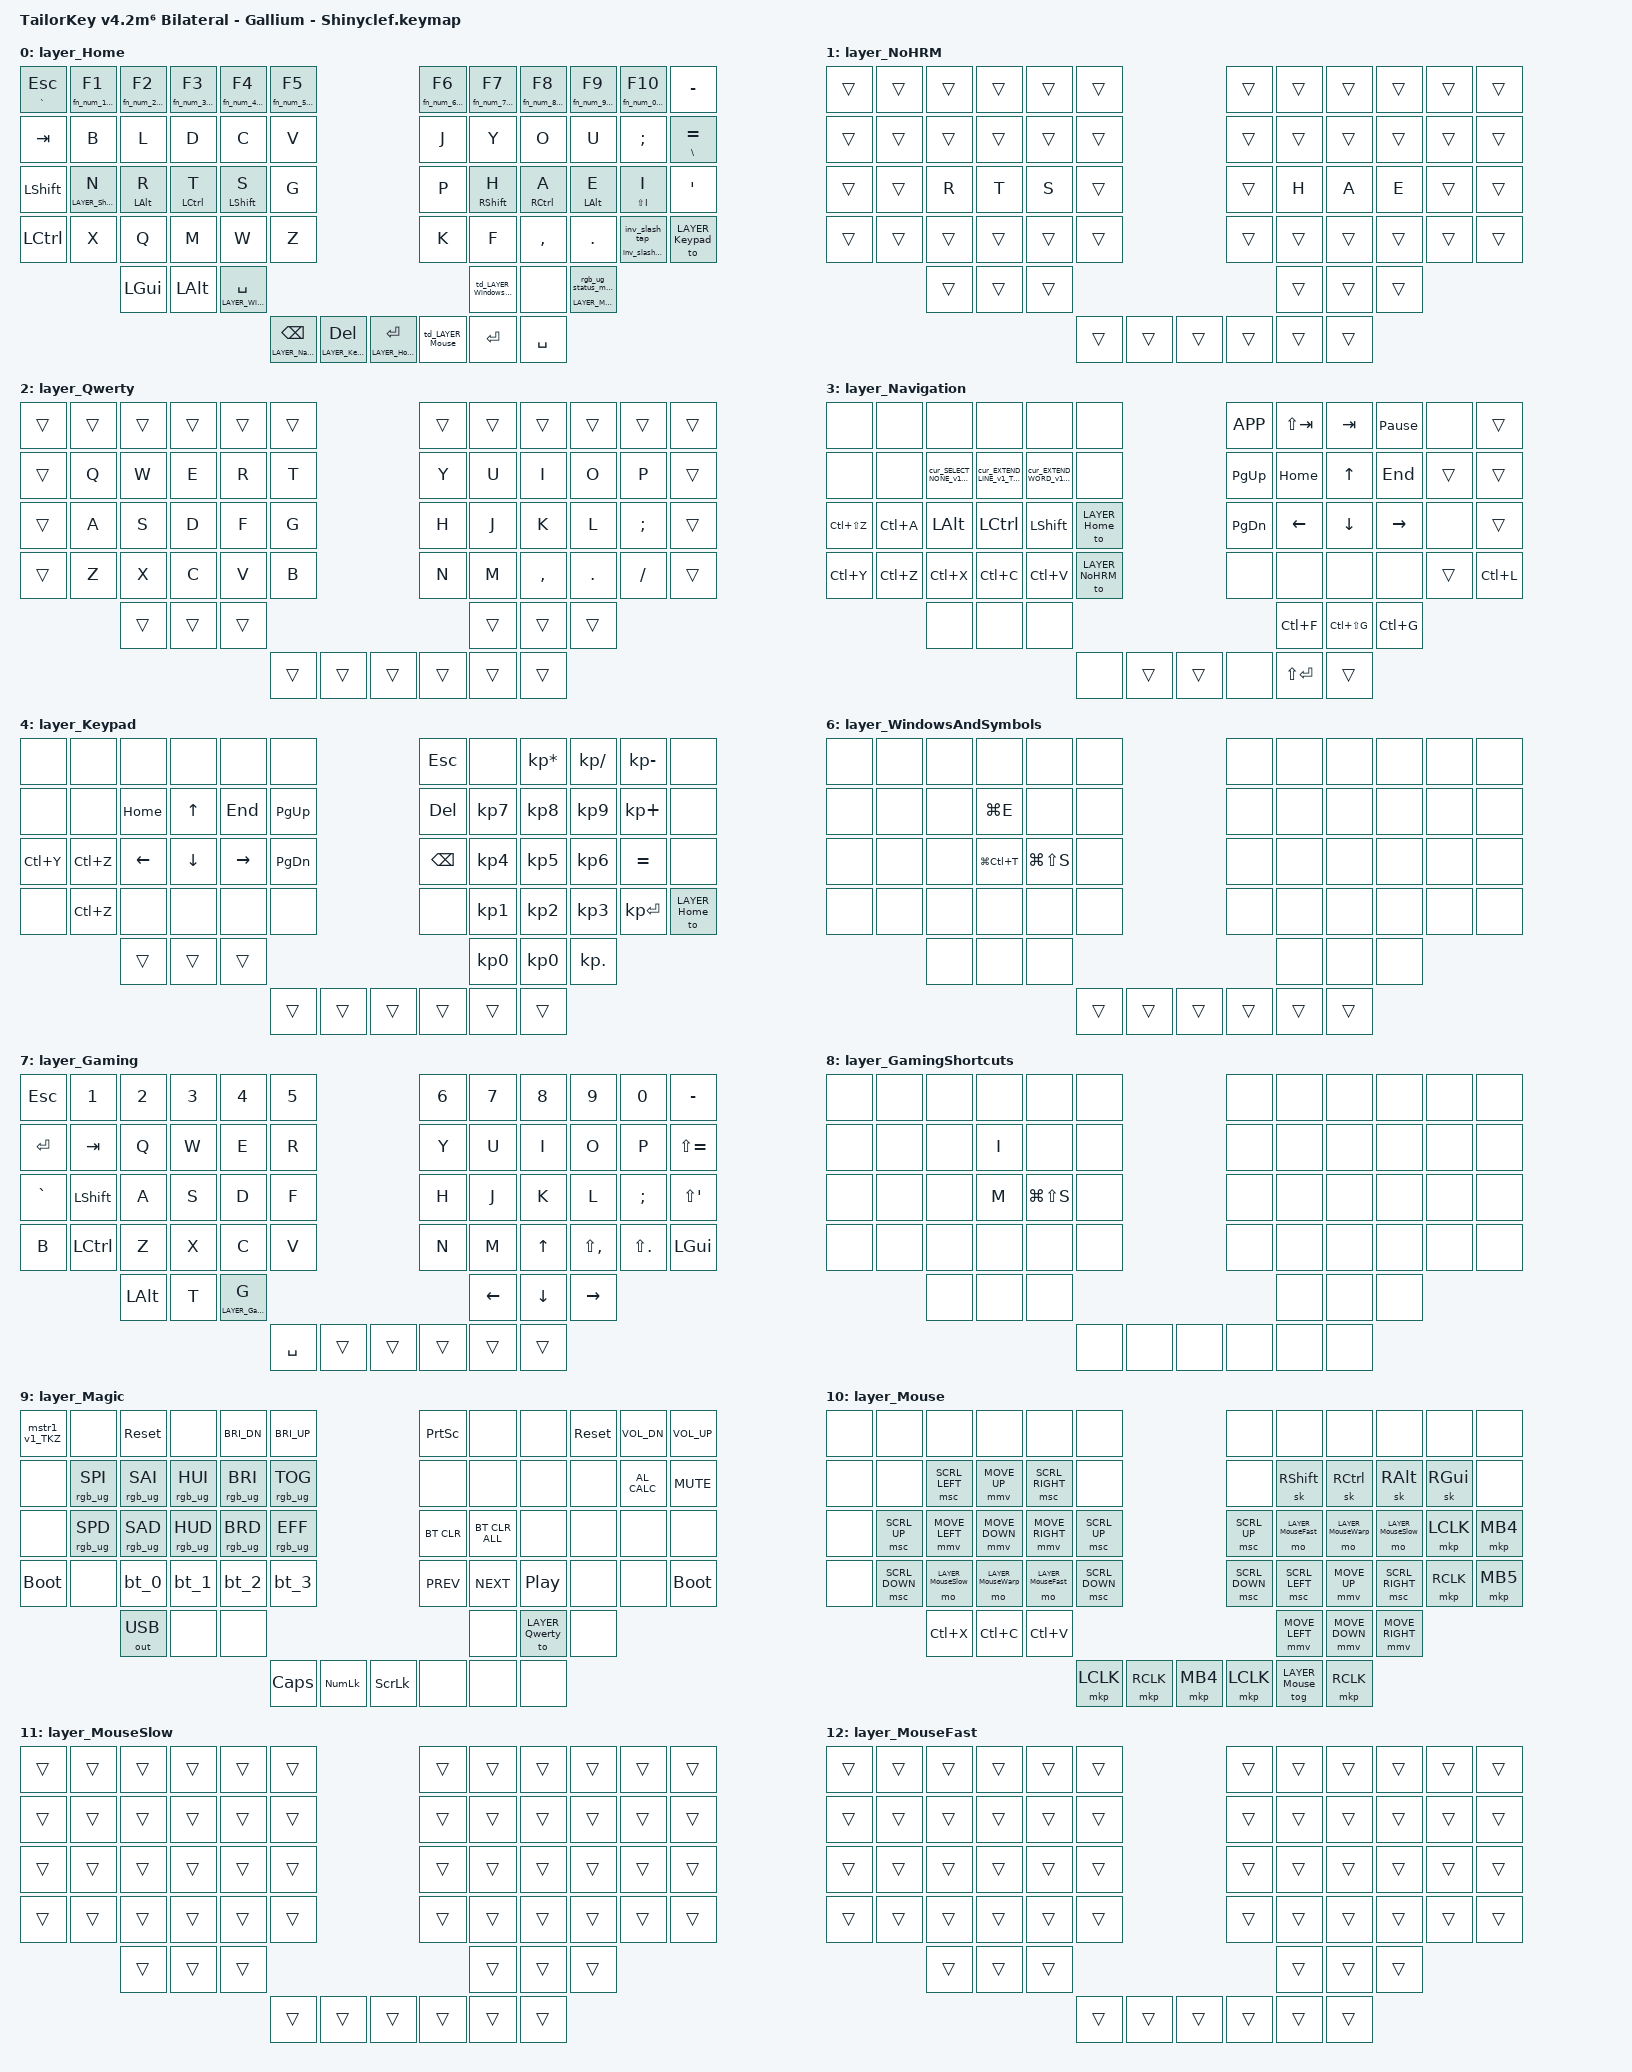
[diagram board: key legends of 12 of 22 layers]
/*
 * Copyright (c) 2020 The ZMK Contributors
 * Copyright (c) 2025 Innaworks Development Limited, trading as MoErgo
 *
 * SPDX-License-Identifier: MIT
 */


/* THIS FILE WAS GENERATED BY GO60 LAYOUT EDITOR
 *
 * This file was generated automatically. You may or may not want to
 * edit it directly.
 */

#include <behaviors.dtsi>

/* Include all behavior includes needed */

#include <dt-bindings/zmk/outputs.h>
#include <dt-bindings/zmk/keys.h>
#include <dt-bindings/zmk/bt.h>
#include <dt-bindings/zmk/rgb.h>

#include <input/processors.dtsi>
#include <dt-bindings/zmk/input_transform.h>
#include <zephyr/dt-bindings/input/input-event-codes.h>

/* On demand includes */
#include <dt-bindings/zmk/input_transform.h>
#include <dt-bindings/zmk/pointing.h>
#include <input/processors.dtsi>

/* Helper Macros, based on https://github.com/urob/zmk-helpers/ */

#pragma once

#define ZMK_HELPER_STRINGIFY(x) #x

// Preprocessor mechanism to overload macros, cf. https://stackoverflow.com/a/27051616/6114651
#define VARGS_(_10, _9, _8, _7, _6, _5, _4, _3, _2, _1, N, ...) N
#define VARGS(...) VARGS_(__VA_ARGS__, 10, 9, 8, 7, 6, 5, 4, 3, 2, 1, 0)
#define CONCAT_(a, b) a##b
#define CONCAT(a, b) CONCAT_(a, b)

#define ZMK_BEHAVIOR_CORE_tap_dance  \
    compatible = "zmk,behavior-tap-dance"; \
    #binding-cells = <0>

#define ZMK_BEHAVIOR(name, type, ...) \
    name: name { \
        ZMK_BEHAVIOR_CORE_ ## type; \
        __VA_ARGS__ \
    };

#define ZMK_TAP_DANCE(name, ...) \
    ZMK_BEHAVIOR(name, tap_dance, __VA_ARGS__)

#define ZMK_TD_LAYER(name, layer) \
    ZMK_TAP_DANCE(name, \
        tapping-term-ms = <200>; \
        bindings = <&mo layer>, <&to layer>; \
)





/* Key positions */

#define POS_LH_C6R1 0
#define POS_LH_C5R1 1
#define POS_LH_C4R1 2
#define POS_LH_C3R1 3
#define POS_LH_C2R1 4
#define POS_LH_C1R1 5
#define POS_RH_C1R1 6
#define POS_RH_C2R1 7
#define POS_RH_C3R1 8
#define POS_RH_C4R1 9
#define POS_RH_C5R1 10
#define POS_RH_C6R1 11
#define POS_LH_C6R2 12
#define POS_LH_C5R2 13
#define POS_LH_C4R2 14
#define POS_LH_C3R2 15
#define POS_LH_C2R2 16
#define POS_LH_C1R2 17
#define POS_RH_C1R2 18
#define POS_RH_C2R2 19
#define POS_RH_C3R2 20
#define POS_RH_C4R2 21
#define POS_RH_C5R2 22
#define POS_RH_C6R2 23
#define POS_LH_C6R3 24
#define POS_LH_C5R3 25
#define POS_LH_C4R3 26
#define POS_LH_C3R3 27
#define POS_LH_C2R3 28
#define POS_LH_C1R3 29
#define POS_RH_C1R3 30
#define POS_RH_C2R3 31
#define POS_RH_C3R3 32
#define POS_RH_C4R3 33
#define POS_RH_C5R3 34
#define POS_RH_C6R3 35
#define POS_LH_C6R4 36
#define POS_LH_C5R4 37
#define POS_LH_C4R4 38
#define POS_LH_C3R4 39
#define POS_LH_C2R4 40
#define POS_LH_C1R4 41
#define POS_RH_C1R4 42
#define POS_RH_C2R4 43
#define POS_RH_C3R4 44
#define POS_RH_C4R4 45
#define POS_RH_C5R4 46
#define POS_RH_C6R4 47
#define POS_LH_C4R5 48
#define POS_LH_C3R5 49
#define POS_LH_C2R5 50
#define POS_RH_C2R5 51
#define POS_RH_C3R5 52
#define POS_RH_C4R5 53
#define POS_LH_T1 54
#define POS_LH_T2 55
#define POS_LH_T3 56
#define POS_RH_T3 57
#define POS_RH_T2 58
#define POS_RH_T1 59


#define LEFT_HAND_KEYS \
  POS_LH_C1R1 POS_LH_C2R1 POS_LH_C3R1 POS_LH_C4R1 POS_LH_C5R1 POS_LH_C6R1 \
  POS_LH_C1R2 POS_LH_C2R2 POS_LH_C3R2 POS_LH_C4R2 POS_LH_C5R2 POS_LH_C6R2 \
  POS_LH_C1R3 POS_LH_C2R3 POS_LH_C3R3 POS_LH_C4R3 POS_LH_C5R3 POS_LH_C6R3 \
  POS_LH_C1R4 POS_LH_C2R4 POS_LH_C3R4 POS_LH_C4R4 POS_LH_C5R4 POS_LH_C6R4 \
              POS_LH_C2R5 POS_LH_C3R5 POS_LH_C4R5

#define RIGHT_HAND_KEYS \
  POS_RH_C1R1 POS_RH_C2R1 POS_RH_C3R1 POS_RH_C4R1 POS_RH_C5R1 POS_RH_C6R1 \
  POS_RH_C1R2 POS_RH_C2R2 POS_RH_C3R2 POS_RH_C4R2 POS_RH_C5R2 POS_RH_C6R2 \
  POS_RH_C1R3 POS_RH_C2R3 POS_RH_C3R3 POS_RH_C4R3 POS_RH_C5R3 POS_RH_C6R3 \
  POS_RH_C1R4 POS_RH_C2R4 POS_RH_C3R4 POS_RH_C4R4 POS_RH_C5R4 POS_RH_C6R4 \
              POS_RH_C2R5 POS_RH_C3R5 POS_RH_C4R5

#define THUMB_KEYS \
  POS_LH_T1 POS_LH_T2 POS_LH_T3 \
  POS_RH_T1 POS_RH_T2 POS_RH_T3

/* Environment and metadata defines */
#define KB_TYPE_GLOVE_80 1
#define KB_TYPE_GO_60    2

#define KB_TYPE          KB_TYPE_GO_60
#define EDITOR_HOST_OS   'W'

/* Automatically generated layer name defines */
#define LAYER_Home 0
#define LAYER_NoHRM 1
#define LAYER_Qwerty 2
#define LAYER_Navigation 3
#define LAYER_Keypad 4
#define LAYER_Shortcuts 5
#define LAYER_WindowsAndSymbols 6
#define LAYER_Gaming 7
#define LAYER_GamingShortcuts 8
#define LAYER_Magic 9
#define LAYER_Mouse 10
#define LAYER_MouseSlow 11
#define LAYER_MouseFast 12
#define LAYER_MouseWarp 13
#define LAYER_LeftPinky 14
#define LAYER_LeftRingy 15
#define LAYER_LeftMiddy 16
#define LAYER_LeftIndex 17
#define LAYER_RightPinky 18
#define LAYER_RightRingy 19
#define LAYER_RightMiddy 20
#define LAYER_RightIndex 21

/* To deal with the situation where there is no Lower layer, to keep &lower happy */
#ifndef LAYER_Lower
#define LAYER_Lower 0
#endif

/* Generated input processors */
/ {
    input_processors {
        zip_click_to_right_click_mapper: zip_click_to_right_click_mapper {
            compatible = "zmk,input-processor-code-mapper";
            #input-processor-cells = <0>;
            type = <INPUT_EV_KEY>;
            map = <INPUT_BTN_0 INPUT_BTN_1>;
        };
    };
};

/* Custom Device-tree */


/* Input Listeners */
&mmv_input_listener {
    // LAYER_MouseSlow
    LAYER_MouseSlow {
        layers = <LAYER_MouseSlow>;
        input-processors = <&zip_xy_scaler 1 9>;
    };
    // LAYER_MouseFast
    LAYER_MouseFast {
        layers = <LAYER_MouseFast>;
        input-processors = <&zip_xy_scaler 3 1>;
    };
    // LAYER_MouseWarp
    LAYER_MouseWarp {
        layers = <LAYER_MouseWarp>;
        input-processors = <&zip_xy_scaler 12 1>;
    };
};

&msc_input_listener {
    // LAYER_MouseSlow
    LAYER_MouseSlow {
        layers = <LAYER_MouseSlow>;
        input-processors = <&zip_scroll_scaler 1 9>;
    };
    // LAYER_MouseFast
    LAYER_MouseFast {
        layers = <LAYER_MouseFast>;
        input-processors = <&zip_scroll_scaler 3 1>;
    };
    // LAYER_MouseWarp
    LAYER_MouseWarp {
        layers = <LAYER_MouseWarp>;
        input-processors = <&zip_scroll_scaler 12 1>;
    };
};

&cirque_lh_listener {
    input-processors = <&zip_xy_scaler 11 12>, <&zip_xy_transform INPUT_TRANSFORM_Y_INVERT>, <&zip_xy_to_scroll_mapper>, <&zip_click_to_right_click_mapper>, <&zip_temp_layer LAYER_Mouse 250>;
    layer_MouseSlow {
        layers = <LAYER_MouseSlow>;
        input-processors = <&zip_xy_scaler 5 14>, <&zip_xy_transform INPUT_TRANSFORM_Y_INVERT>, <&zip_xy_to_scroll_mapper>, <&zip_click_to_right_click_mapper>;
    };
    layer_MouseFast {
        layers = <LAYER_MouseFast>;
        input-processors = <&zip_xy_scaler 3 2>, <&zip_xy_transform INPUT_TRANSFORM_Y_INVERT>, <&zip_xy_to_scroll_mapper>, <&zip_click_to_right_click_mapper>;
    };
    layer_MouseWarp {
        layers = <LAYER_MouseWarp>;
        input-processors = <&zip_xy_scaler 13 3>, <&zip_xy_transform INPUT_TRANSFORM_Y_INVERT>, <&zip_xy_to_scroll_mapper>, <&zip_click_to_right_click_mapper>;
    };
};

&cirque_rh_listener {
    input-processors = <&zip_xy_scaler 5 2>, <&zip_temp_layer LAYER_Mouse 250>;
    layer_MouseSlow {
        layers = <LAYER_MouseSlow>;
        input-processors = <&zip_xy_scaler 1 1>;
    };
    layer_MouseFast {
        layers = <LAYER_MouseFast>;
        input-processors = <&zip_xy_scaler 4 1>;
    };
    layer_MouseWarp {
        layers = <LAYER_MouseWarp>;
        input-processors = <&zip_xy_scaler 6 1>;
    };
};

/* System behavior and macros */
/ {
    behaviors {
        ZMK_TD_LAYER(lower, LAYER_Lower)
    };
};

/ {
    macros {
        rgb_ug_status_macro: rgb_ug_status_macro {
            label = "RGB_UG_STATUS";
            compatible = "zmk,behavior-macro";
            #binding-cells = <0>;
            bindings
                = <&rgb_ug RGB_STATUS>;
        };
    };
};

/ {
#ifdef BT_DISC_CMD
    behaviors {
        bt_0: bt_0 {
            compatible = "zmk,behavior-tap-dance";
            label = "BT_0";
            #binding-cells = <0>;
            tapping-term-ms = <200>;
            bindings = <&bt_select_0>, <&bt BT_DISC 0>;
        };
        bt_1: bt_1 {
            compatible = "zmk,behavior-tap-dance";
            label = "BT_1";
            #binding-cells = <0>;
            tapping-term-ms = <200>;
            bindings = <&bt_select_1>, <&bt BT_DISC 1>;
        };
        bt_2: bt_2 {
            compatible = "zmk,behavior-tap-dance";
            label = "BT_2";
            #binding-cells = <0>;
            tapping-term-ms = <200>;
            bindings = <&bt_select_2>, <&bt BT_DISC 2>;
        };
        bt_3: bt_3 {
            compatible = "zmk,behavior-tap-dance";
            label = "BT_3";
            #binding-cells = <0>;
            tapping-term-ms = <200>;
            bindings = <&bt_select_3>, <&bt BT_DISC 3>;
        };
    };
    macros {
        bt_select_0: bt_select_0 {
            label = "BT_SELECT_0";
            compatible = "zmk,behavior-macro";
            #binding-cells = <0>;
            bindings
                = <&out OUT_BLE>,
                  <&bt BT_SEL 0>;
        };
        bt_select_1: bt_select_1 {
            label = "BT_SELECT_1";
            compatible = "zmk,behavior-macro";
            #binding-cells = <0>;
            bindings
                = <&out OUT_BLE>,
                  <&bt BT_SEL 1>;
        };
        bt_select_2: bt_select_2 {
            label = "BT_SELECT_2";
            compatible = "zmk,behavior-macro";
            #binding-cells = <0>;
            bindings
                = <&out OUT_BLE>,
                  <&bt BT_SEL 2>;
        };
        bt_select_3: bt_select_3 {
            label = "BT_SELECT_3";
            compatible = "zmk,behavior-macro";
            #binding-cells = <0>;
            bindings
                = <&out OUT_BLE>,
                  <&bt BT_SEL 3>;
        };
    };
#else
    macros {
        bt_0: bt_0 {
            label = "BT_0";
            compatible = "zmk,behavior-macro";
            #binding-cells = <0>;
            bindings
                = <&out OUT_BLE>,
                  <&bt BT_SEL 0>;
        };
        bt_1: bt_1 {
            label = "BT_1";
            compatible = "zmk,behavior-macro";
            #binding-cells = <0>;
            bindings
                = <&out OUT_BLE>,
                  <&bt BT_SEL 1>;
        };
        bt_2: bt_2 {
            label = "BT_2";
            compatible = "zmk,behavior-macro";
            #binding-cells = <0>;
            bindings
                = <&out OUT_BLE>,
                  <&bt BT_SEL 2>;
        };
        bt_3: bt_3 {
            label = "BT_3";
            compatible = "zmk,behavior-macro";
            #binding-cells = <0>;
            bindings
                = <&out OUT_BLE>,
                  <&bt BT_SEL 3>;
        };
    };
#endif
};

/ {
    behaviors {
        magic: magic {
            compatible = "zmk,behavior-hold-tap";
            label = "MAGIC_HOLD_TAP";
            #binding-cells = <2>;
            flavor = "tap-preferred";
            tapping-term-ms = <200>;
            bindings = <&mo>, <&rgb_ug_status_macro>;
        };
    };
};


/* Custom Defined Behaviors */
/ {
behaviors {
    /*
     * ? / key
     *
     * No Shift:
     *   tap                  = ?
     *   hold alone           = /
     *   press another key    = ?
     *
     * Shift:
     *   always /
     */

    inv_slash_hold: inverted_slash_hold {
        compatible = "zmk,behavior-mod-morph";
        #binding-cells = <0>;

        bindings = <&kp SLASH>, <&kp SLASH>;
        mods = <(MOD_LSFT | MOD_RSFT)>;
    };

    inv_slash_tap: inverted_slash_tap {
        compatible = "zmk,behavior-mod-morph";
        #binding-cells = <0>;

        bindings = <&kp QUESTION>, <&kp SLASH>;
        mods = <(MOD_LSFT | MOD_RSFT)>;
    };

    inv_slash: inverted_slash {
        compatible = "zmk,behavior-hold-tap";
        #binding-cells = <2>;

        flavor = "hold-preferred";
        tapping-term-ms = <200>;

        /*
         * Dummy, unreachable GO60 position.
         *
         * Because every real key is outside this list, pressing any
         * other key while inv_slash is undecided forces the tap action.
         *
         * Holding inv_slash by itself still produces the hold action.
         */
        hold-trigger-key-positions = <999>;

        bindings = <&inv_slash_hold>, <&inv_slash_tap>;
    };


        /*
     * Number keys
     *
     * Example for 1:
     *   tap        = F1
     *   Shift+tap  = Shift+F1
     *   hold       = !
     *   Shift+hold = 1
     *
     * Hold-preferred means pressing another key while the
     * number key is held selects the hold output.
     */


    /*
     * Hold outputs
     *
     * Without Shift: symbol
     * With Shift:    plain number
     *
     * Mod-morph removes Shift from the shifted branch,
     * allowing &kp N1 to output 1 rather than !.
     */

    fn_num_1_hold: fn_number_1_hold {
        compatible = "zmk,behavior-mod-morph";
        #binding-cells = <0>;

        bindings = <&kp EXCL>, <&kp N1>;
        mods = <(MOD_LSFT | MOD_RSFT)>;
    };

    fn_num_2_hold: fn_number_2_hold {
        compatible = "zmk,behavior-mod-morph";
        #binding-cells = <0>;

        bindings = <&kp AT>, <&kp N2>;
        mods = <(MOD_LSFT | MOD_RSFT)>;
    };

    fn_num_3_hold: fn_number_3_hold {
        compatible = "zmk,behavior-mod-morph";
        #binding-cells = <0>;

        bindings = <&kp HASH>, <&kp N3>;
        mods = <(MOD_LSFT | MOD_RSFT)>;
    };

    fn_num_4_hold: fn_number_4_hold {
        compatible = "zmk,behavior-mod-morph";
        #binding-cells = <0>;

        bindings = <&kp DLLR>, <&kp N4>;
        mods = <(MOD_LSFT | MOD_RSFT)>;
    };

    fn_num_5_hold: fn_number_5_hold {
        compatible = "zmk,behavior-mod-morph";
        #binding-cells = <0>;

        bindings = <&kp PRCNT>, <&kp N5>;
        mods = <(MOD_LSFT | MOD_RSFT)>;
    };

    fn_num_6_hold: fn_number_6_hold {
        compatible = "zmk,behavior-mod-morph";
        #binding-cells = <0>;

        bindings = <&kp CARET>, <&kp N6>;
        mods = <(MOD_LSFT | MOD_RSFT)>;
    };

    fn_num_7_hold: fn_number_7_hold {
        compatible = "zmk,behavior-mod-morph";
        #binding-cells = <0>;

        bindings = <&kp AMPS>, <&kp N7>;
        mods = <(MOD_LSFT | MOD_RSFT)>;
    };

    fn_num_8_hold: fn_number_8_hold {
        compatible = "zmk,behavior-mod-morph";
        #binding-cells = <0>;

        bindings = <&kp STAR>, <&kp N8>;
        mods = <(MOD_LSFT | MOD_RSFT)>;
    };

    fn_num_9_hold: fn_number_9_hold {
        compatible = "zmk,behavior-mod-morph";
        #binding-cells = <0>;

        bindings = <&kp LPAR>, <&kp N9>;
        mods = <(MOD_LSFT | MOD_RSFT)>;
    };

    fn_num_0_hold: fn_number_0_hold {
        compatible = "zmk,behavior-mod-morph";
        #binding-cells = <0>;

        bindings = <&kp RPAR>, <&kp N0>;
        mods = <(MOD_LSFT | MOD_RSFT)>;
    };


    /*
     * Outer hold-taps
     *
     * Parameter 1 is a dummy value for the zero-parameter
     * hold mod-morph.
     *
     * Parameter 2 is the F-key used by the tap branch.
     */

    fn_num_1: fn_number_1 {
        compatible = "zmk,behavior-hold-tap";
        #binding-cells = <2>;

        flavor = "hold-preferred";
        tapping-term-ms = <200>;

        bindings = <&fn_num_1_hold>, <&kp>;
    };

    fn_num_2: fn_number_2 {
        compatible = "zmk,behavior-hold-tap";
        #binding-cells = <2>;

        flavor = "hold-preferred";
        tapping-term-ms = <200>;

        bindings = <&fn_num_2_hold>, <&kp>;
    };

    fn_num_3: fn_number_3 {
        compatible = "zmk,behavior-hold-tap";
        #binding-cells = <2>;

        flavor = "hold-preferred";
        tapping-term-ms = <200>;

        bindings = <&fn_num_3_hold>, <&kp>;
    };

    fn_num_4: fn_number_4 {
        compatible = "zmk,behavior-hold-tap";
        #binding-cells = <2>;

        flavor = "hold-preferred";
        tapping-term-ms = <200>;

        bindings = <&fn_num_4_hold>, <&kp>;
    };

    fn_num_5: fn_number_5 {
        compatible = "zmk,behavior-hold-tap";
        #binding-cells = <2>;

        flavor = "hold-preferred";
        tapping-term-ms = <200>;

        bindings = <&fn_num_5_hold>, <&kp>;
    };

    fn_num_6: fn_number_6 {
        compatible = "zmk,behavior-hold-tap";
        #binding-cells = <2>;

        flavor = "hold-preferred";
        tapping-term-ms = <200>;

        bindings = <&fn_num_6_hold>, <&kp>;
    };

    fn_num_7: fn_number_7 {
        compatible = "zmk,behavior-hold-tap";
        #binding-cells = <2>;

        flavor = "hold-preferred";
        tapping-term-ms = <200>;

        bindings = <&fn_num_7_hold>, <&kp>;
    };

    fn_num_8: fn_number_8 {
        compatible = "zmk,behavior-hold-tap";
        #binding-cells = <2>;

        flavor = "hold-preferred";
        tapping-term-ms = <200>;

        bindings = <&fn_num_8_hold>, <&kp>;
    };

    fn_num_9: fn_number_9 {
        compatible = "zmk,behavior-hold-tap";
        #binding-cells = <2>;

        flavor = "hold-preferred";
        tapping-term-ms = <200>;

        bindings = <&fn_num_9_hold>, <&kp>;
    };

    fn_num_0: fn_number_0 {
        compatible = "zmk,behavior-hold-tap";
        #binding-cells = <2>;

        flavor = "hold-preferred";
        tapping-term-ms = <200>;

        bindings = <&fn_num_0_hold>, <&kp>;
    };
};
};

/* Automatically generated macro definitions */
/ {
    macros {

        // Cursor Layer - Extent Line (seq) - TailorKey
        cur_EXTEND_LINE_v1_TKZ: cur_EXTEND_LINE_v1_TKZ {
            label = "&CUR_EXTEND_LINE_V1_TKZ";
            compatible = "zmk,behavior-macro";
            #binding-cells = <0>;
            tap-ms = <1>;
            wait-ms = <1>;
            bindings = <&kp LS(END)>;
        };

        // Cursor Layer - Extend Word (seq) - TailorKey
        cur_EXTEND_WORD_v1_TKZ: cur_EXTEND_WORD_v1_TKZ {
            label = "&CUR_EXTEND_WORD_V1_TKZ";
            compatible = "zmk,behavior-macro";
            #binding-cells = <0>;
            tap-ms = <1>;
            wait-ms = <1>;
            bindings = <&kp LC(LS(RIGHT))>;
        };

        // Cursor Layer - Select Line (seq) - TailorKey
        cur_SELECT_LINE_v1_TKZ: cur_SELECT_LINE_v1_TKZ {
            label = "&CUR_SELECT_LINE_V1_TKZ";
            compatible = "zmk,behavior-macro";
            #binding-cells = <0>;
            tap-ms = <1>;
            wait-ms = <1>;
            bindings = <&kp HOME>
                , <&kp LS(END)>;
        };

        // Cursor Layer - Select None (seq) - TailorKey
        cur_SELECT_NONE_v1_TKZ: cur_SELECT_NONE_v1_TKZ {
            label = "&CUR_SELECT_NONE_V1_TKZ";
            compatible = "zmk,behavior-macro";
            #binding-cells = <0>;
            tap-ms = <1>;
            wait-ms = <1>;
            bindings = <&kp DOWN>
                , <&kp UP>
                , <&kp RIGHT>
                , <&kp LEFT>;
        };

        // Cursor Layer - Select Word (seq) - TailorKey
        cur_SELECT_WORD_v1_TKZ: cur_SELECT_WORD_v1_TKZ {
            label = "&CUR_SELECT_WORD_V1_TKZ";
            compatible = "zmk,behavior-macro";
            #binding-cells = <0>;
            tap-ms = <1>;
            wait-ms = <1>;
            bindings = <&kp LC(LEFT)>
                , <&kp LC(LS(RIGHT))>;
        };

        // HRM_left_index_hold -> swich layer  - TailorKey
        HRM_left_index_hold_v1B_TKZ: HRM_left_index_hold_v1B_TKZ {
            label = "&HRM_LEFT_INDEX_HOLD_V1B_TKZ";
            compatible = "zmk,behavior-macro-one-param";
            #binding-cells = <1>;
            tap-ms = <0>;
            wait-ms = <0>;
            bindings = <&macro_press>
                , <&macro_param_1to1>
                , <&kp MACRO_PLACEHOLDER>
                , <&mo LAYER_LeftIndex>
                , <&macro_pause_for_release>
                , <&macro_release>
                , <&macro_param_1to1>
                , <&kp MACRO_PLACEHOLDER>
                , <&mo LAYER_LeftIndex>;
        };

        // HRM_left_index_tap - incl. alpha character
        HRM_left_index_tap_v1B_TKZ: HRM_left_index_tap_v1B_TKZ {
            label = "&HRM_LEFT_INDEX_TAP_V1B_TKZ";
            compatible = "zmk,behavior-macro-one-param";
            #binding-cells = <1>;
            tap-ms = <0>;
            wait-ms = <0>;
            bindings = <&macro_release>
                , <&kp LSHFT>
                , <&kp RSHFT>
                , <&kp LALT>
                , <&kp RALT>
                , <&kp LCTRL>
                , <&kp RCTRL>
                , <&kp LGUI>
                , <&kp RGUI>
                , <&macro_tap>
                , <&kp S>
                , <&macro_tap>
                , <&macro_param_1to1>
                , <&kp MACRO_PLACEHOLDER>;
        };

        // HRM_left_middy_hold -> swich layer - TailorKey
        HRM_left_middy_hold_v1B_TKZ: HRM_left_middy_hold_v1B_TKZ {
            label = "&HRM_LEFT_MIDDY_HOLD_V1B_TKZ";
            compatible = "zmk,behavior-macro-one-param";
            #binding-cells = <1>;
            tap-ms = <0>;
            wait-ms = <0>;
            bindings = <&macro_press>
                , <&macro_param_1to1>
                , <&kp MACRO_PLACEHOLDER>
                , <&mo LAYER_LeftMiddy>
                , <&macro_pause_for_release>
                , <&macro_release>
                , <&macro_param_1to1>
                , <&kp MACRO_PLACEHOLDER>
                , <&mo LAYER_LeftMiddy>;
        };

        // HRM_left_middy_tap - incl. alpha character
        HRM_left_middy_tap_v1B_TKZ: HRM_left_middy_tap_v1B_TKZ {
            label = "&HRM_LEFT_MIDDY_TAP_V1B_TKZ";
            compatible = "zmk,behavior-macro-one-param";
            #binding-cells = <1>;
            tap-ms = <0>;
            wait-ms = <0>;
            bindings = <&macro_release>
                , <&kp LSHFT>
                , <&kp RSHFT>
                , <&kp LALT>
                , <&kp RALT>
                , <&kp LCTRL>
                , <&kp RCTRL>
                , <&kp LGUI>
                , <&kp RGUI>
                , <&macro_tap>
                , <&kp T>
                , <&macro_tap>
                , <&macro_param_1to1>
                , <&kp MACRO_PLACEHOLDER>;
        };

        // HRM_left_pinky_hold -> swich layer - TailorKey
        HRM_left_pinky_hold_v1B_TKZ: HRM_left_pinky_hold_v1B_TKZ {
            label = "&HRM_LEFT_PINKY_HOLD_V1B_TKZ";
            compatible = "zmk,behavior-macro-one-param";
            #binding-cells = <1>;
            tap-ms = <0>;
            wait-ms = <0>;
            bindings = <&macro_press>
                , <&macro_param_1to1>
                , <&kp A>
                , <&mo LAYER_LeftPinky>
                , <&macro_pause_for_release>
                , <&macro_release>
                , <&macro_param_1to1>
                , <&kp A>
                , <&mo LAYER_LeftPinky>;
        };

        // HRM_left_pinky_tap - incl. alpha character
        HRM_left_pinky_tap_v1B_TKZ: HRM_left_pinky_tap_v1B_TKZ {
            label = "&HRM_LEFT_PINKY_TAP_V1B_TKZ";
            compatible = "zmk,behavior-macro-one-param";
            #binding-cells = <1>;
            tap-ms = <0>;
            wait-ms = <0>;
            bindings = <&macro_release>
                , <&kp LSHFT>
                , <&kp RSHFT>
                , <&kp LALT>
                , <&kp RALT>
                , <&kp LCTRL>
                , <&kp RCTRL>
                , <&kp LGUI>
                , <&kp RGUI>
                , <&macro_tap>
                , <&kp N>
                , <&macro_tap>
                , <&macro_param_1to1>
                , <&kp MACRO_PLACEHOLDER>;
        };

        // HRM_left_ring_hold -> swich layer - TailorKey
        HRM_left_ring_hold_v1B_TKZ: HRM_left_ring_hold_v1B_TKZ {
            label = "&HRM_LEFT_RING_HOLD_V1B_TKZ";
            compatible = "zmk,behavior-macro-one-param";
            #binding-cells = <1>;
            tap-ms = <0>;
            wait-ms = <0>;
            bindings = <&macro_press>
                , <&macro_param_1to1>
                , <&kp MACRO_PLACEHOLDER>
                , <&mo LAYER_LeftRingy>
                , <&macro_pause_for_release>
                , <&macro_release>
                , <&macro_param_1to1>
                , <&kp MACRO_PLACEHOLDER>
                , <&mo LAYER_LeftRingy>;
        };

        // HRM_left_ring_tap - incl. alpha character
        HRM_left_ring_tap_v1B_TKZ: HRM_left_ring_tap_v1B_TKZ {
            label = "&HRM_LEFT_RING_TAP_V1B_TKZ";
            compatible = "zmk,behavior-macro-one-param";
            #binding-cells = <1>;
            tap-ms = <0>;
            wait-ms = <0>;
            bindings = <&macro_release>
                , <&kp LSHFT>
                , <&kp RSHFT>
                , <&kp LALT>
                , <&kp RALT>
                , <&kp LCTRL>
                , <&kp RCTRL>
                , <&kp LGUI>
                , <&kp RGUI>
                , <&macro_tap>
                , <&kp R>
                , <&macro_tap>
                , <&macro_param_1to1>
                , <&kp MACRO_PLACEHOLDER>;
        };

        // HRM_right_index_hold -> swich layer - TailorKey
        HRM_right_index_hold_v1B_TKZ: HRM_right_index_hold_v1B_TKZ {
            label = "&HRM_RIGHT_INDEX_HOLD_V1B_TKZ";
            compatible = "zmk,behavior-macro-one-param";
            #binding-cells = <1>;
            tap-ms = <0>;
            wait-ms = <0>;
            bindings = <&macro_press>
                , <&macro_param_1to1>
                , <&kp MACRO_PLACEHOLDER>
                , <&mo LAYER_RightIndex>
                , <&macro_pause_for_release>
                , <&macro_release>
                , <&macro_param_1to1>
                , <&kp MACRO_PLACEHOLDER>
                , <&mo LAYER_RightIndex>;
        };

        // HRM_right_index_tap - incl. alpha character
        HRM_right_index_tap_v1B_TKZ: HRM_right_index_tap_v1B_TKZ {
            label = "&HRM_RIGHT_INDEX_TAP_V1B_TKZ";
            compatible = "zmk,behavior-macro-one-param";
            #binding-cells = <1>;
            tap-ms = <0>;
            wait-ms = <0>;
            bindings = <&macro_release>
                , <&kp LSHFT>
                , <&kp RSHFT>
                , <&kp LALT>
                , <&kp RALT>
                , <&kp LCTRL>
                , <&kp RCTRL>
                , <&kp LGUI>
                , <&kp RGUI>
                , <&macro_tap>
                , <&kp H>
                , <&macro_tap>
                , <&macro_param_1to1>
                , <&kp MACRO_PLACEHOLDER>;
        };

        // HRM_right_middy_hold -> swich layer - TailorKey
        HRM_right_middy_hold_v1B_TKZ: HRM_right_middy_hold_v1B_TKZ {
            label = "&HRM_RIGHT_MIDDY_HOLD_V1B_TKZ";
            compatible = "zmk,behavior-macro-one-param";
            #binding-cells = <1>;
            tap-ms = <0>;
            wait-ms = <0>;
            bindings = <&macro_press>
                , <&macro_param_1to1>
                , <&kp MACRO_PLACEHOLDER>
                , <&mo LAYER_RightMiddy>
                , <&macro_pause_for_release>
                , <&macro_release>
                , <&macro_param_1to1>
                , <&kp MACRO_PLACEHOLDER>
                , <&mo LAYER_RightMiddy>;
        };

        // HRM_right_middy_tap - incl. alpha character
        HRM_right_middy_tap_v1B_TKZ: HRM_right_middy_tap_v1B_TKZ {
            label = "&HRM_RIGHT_MIDDY_TAP_V1B_TKZ";
            compatible = "zmk,behavior-macro-one-param";
            #binding-cells = <1>;
            tap-ms = <0>;
            wait-ms = <0>;
            bindings = <&macro_release>
                , <&kp LSHFT>
                , <&kp RSHFT>
                , <&kp LALT>
                , <&kp RALT>
                , <&kp LCTRL>
                , <&kp RCTRL>
                , <&kp LGUI>
                , <&kp RGUI>
                , <&macro_tap>
                , <&kp A>
                , <&macro_tap>
                , <&macro_param_1to1>
                , <&kp MACRO_PLACEHOLDER>;
        };

        // HRM_right_pinky_hold -> swich layer - TailorKey
        HRM_right_pinky_hold_v1B_TKZ: HRM_right_pinky_hold_v1B_TKZ {
            label = "&HRM_RIGHT_PINKY_HOLD_V1B_TKZ";
            compatible = "zmk,behavior-macro-one-param";
            #binding-cells = <1>;
            tap-ms = <0>;
            wait-ms = <0>;
            bindings = <&macro_press>
                , <&macro_param_1to1>
                , <&kp A>
                , <&mo LAYER_RightPinky>
                , <&macro_pause_for_release>
                , <&macro_release>
                , <&macro_param_1to1>
                , <&kp A>
                , <&mo LAYER_RightPinky>;
        };

        // HRM_right_pinky_tap - incl. alpha character
        HRM_right_pinky_tap_v1B_TKZ: HRM_right_pinky_tap_v1B_TKZ {
            label = "&HRM_RIGHT_PINKY_TAP_V1B_TKZ";
            compatible = "zmk,behavior-macro-one-param";
            #binding-cells = <1>;
            tap-ms = <0>;
            wait-ms = <0>;
            bindings = <&macro_release>
                , <&kp LSHFT>
                , <&kp RSHFT>
                , <&kp LALT>
                , <&kp RALT>
                , <&kp LCTRL>
                , <&kp RCTRL>
                , <&kp LGUI>
                , <&kp RGUI>
                , <&macro_tap>
                , <&kp I>
                , <&macro_tap>
                , <&macro_param_1to1>
                , <&kp MACRO_PLACEHOLDER>;
        };

        // HRM_right_ring_hold -> swich layer - TailorKey
        HRM_right_ring_hold_v1B_TKZ: HRM_right_ring_hold_v1B_TKZ {
            label = "&HRM_RIGHT_RING_HOLD_V1B_TKZ";
            compatible = "zmk,behavior-macro-one-param";
            #binding-cells = <1>;
            tap-ms = <0>;
            wait-ms = <0>;
            bindings = <&macro_press>
                , <&macro_param_1to1>
                , <&kp MACRO_PLACEHOLDER>
                , <&mo LAYER_RightRingy>
                , <&macro_pause_for_release>
                , <&macro_release>
                , <&macro_param_1to1>
                , <&kp MACRO_PLACEHOLDER>
                , <&mo LAYER_RightRingy>;
        };

        // HRM_right_ring_tap - incl. alpha character
        HRM_right_ring_tap_v1B_TKZ: HRM_right_ring_tap_v1B_TKZ {
            label = "&HRM_RIGHT_RING_TAP_V1B_TKZ";
            compatible = "zmk,behavior-macro-one-param";
            #binding-cells = <1>;
            tap-ms = <0>;
            wait-ms = <0>;
            bindings = <&macro_release>
                , <&kp LSHFT>
                , <&kp RSHFT>
                , <&kp LALT>
                , <&kp RALT>
                , <&kp LCTRL>
                , <&kp RCTRL>
                , <&kp LGUI>
                , <&kp RGUI>
                , <&macro_tap>
                , <&kp E>
                , <&macro_tap>
                , <&macro_param_1to1>
                , <&kp MACRO_PLACEHOLDER>;
        };

        // mod_tab_switcher_chord -  TailorKey
        mod_tab_chord_v2_TKZ: mod_tab_chord_v2_TKZ {
            label = "&MOD_TAB_CHORD_V2_TKZ";
            compatible = "zmk,behavior-macro-two-param";
            #binding-cells = <2>;
            tap-ms = <0>;
            wait-ms = <0>;
            bindings = <&macro_press>
                , <&macro_param_2to1>
                , <&mo MACRO_PLACEHOLDER>
                , <&macro_press>
                , <&macro_param_1to1>
                , <&mod_tab_v1_TKZ MACRO_PLACEHOLDER>
                , <&macro_pause_for_release>
                , <&macro_release>
                , <&macro_param_1to1>
                , <&mod_tab_v1_TKZ MACRO_PLACEHOLDER>
                , <&macro_release>
                , <&macro_param_2to1>
                , <&mo MACRO_PLACEHOLDER>;
        };

        // mod_tab_switcher - TailorKey
        //
        //
        mod_tab_v1_TKZ: mod_tab_v1_TKZ {
            label = "&MOD_TAB_V1_TKZ";
            compatible = "zmk,behavior-macro-one-param";
            #binding-cells = <1>;
            tap-ms = <0>;
            wait-ms = <0>;
            bindings = <&macro_press>
                , <&macro_param_1to1>
                , <&kp MACRO_PLACEHOLDER>
                , <&macro_tap>
                , <&kp TAB>
                , <&macro_pause_for_release>
                , <&macro_release>
                , <&macro_param_1to1>
                , <&kp MACRO_PLACEHOLDER>;
        };

        // macro string1 sample - Magic Layer F1 - Text output sample macro 1 "¡Hola!" - TailorKey
        mstr1_v1_TKZ: mstr1_v1_TKZ {
            label = "&MSTR1_V1_TKZ";
            compatible = "zmk,behavior-macro";
            #binding-cells = <0>;
            bindings = <&macro_press>
                , <&kp RALT>
                , <&macro_tap>
                , <&kp KP_N0>
                , <&kp KP_N1>
                , <&kp KP_N6>
                , <&kp KP_N1>
                , <&macro_release>
                , <&kp RALT>
                , <&macro_press>
                , <&kp LSHFT>
                , <&macro_tap>
                , <&kp H>
                , <&macro_release>
                , <&kp LSHFT>
                , <&macro_tap>
                , <&kp O>
                , <&kp L>
                , <&kp A>
                , <&kp LS(N1)>
                , <&kp SPACE>
                , <&kp RET>;
        };

        // Symbol layer dot dot
        symb_dotdot_v1_TKZ: symb_dotdot_v1_TKZ {
            label = "&SYMB_DOTDOT_V1_TKZ";
            compatible = "zmk,behavior-macro";
            #binding-cells = <0>;
            tap-ms = <0>;
            wait-ms = <0>;
            bindings = <&macro_tap>
                , <&kp DOT>
                , <&kp DOT>;
        };
    };
};

/* Automatically generated behavior definitions */
/ {
    behaviors {

        // Layer tap dance behaviors

        ZMK_TD_LAYER(td_LAYER_WindowsAndSymbols, 6)
        ZMK_TD_LAYER(td_LAYER_Mouse, 10)

        // AutoShift Helper - &AS main macro is chained to &AS_HT hold tap and &AS_Shifted macro. For faster typists, it is recommended to decrease the tapping-term-ms value. A suggested value is 135 ms.
        // More: https://github.com/nickcoutsos/keymap-editor/wiki/Autoshift-using-ZMK-behaviors
        AS_HT_v2_TKZ: AS_HT_v2_TKZ {
            compatible = "zmk,behavior-hold-tap";
            #binding-cells = <2>;
            tapping-term-ms = <190>;
            bindings = <&kp>, <&kp>;
            flavor = "tap-preferred";
        };

        // HRM_left_index_middy_bilateral -> &kp - &HRM_left_index_tap - TailorKey
        HRM_left_index_middy_v1B_TKZ: HRM_left_index_middy_v1B_TKZ {
            compatible = "zmk,behavior-hold-tap";
            #binding-cells = <2>;
            tapping-term-ms = <180>;
            bindings = <&kp>, <&HRM_left_index_tap_v1B_TKZ>;
            flavor = "tap-preferred";
            quick-tap-ms = <300>;
            require-prior-idle-ms = <50>;
            hold-trigger-key-positions = <POS_RH_T3 POS_RH_T2 POS_RH_T1 POS_RH_C1R1 POS_RH_C2R1 POS_RH_C3R1 POS_RH_C4R1 POS_RH_C5R1 POS_RH_C1R2 POS_RH_C2R2 POS_RH_C3R2 POS_RH_C4R2 POS_RH_C5R2 POS_RH_C1R3 POS_RH_C2R3 POS_RH_C3R3 POS_RH_C4R3 POS_RH_C5R3 POS_RH_C1R4 POS_RH_C2R4 POS_RH_C3R4 POS_RH_C4R4 POS_RH_C5R4 POS_RH_C2R5 POS_RH_C3R5 POS_RH_C4R5 POS_RH_C6R1 POS_RH_C6R2 POS_RH_C6R3 POS_RH_C6R4>;
            hold-trigger-on-release;
        };

        // HRM_left_index_pinky_bilateral -> &kp - &HRM_left_index_tap - TailorKey
        HRM_left_index_pinky_v1B_TKZ: HRM_left_index_pinky_v1B_TKZ {
            compatible = "zmk,behavior-hold-tap";
            #binding-cells = <2>;
            tapping-term-ms = <180>;
            bindings = <&kp>, <&HRM_left_index_tap_v1B_TKZ>;
            flavor = "tap-preferred";
            quick-tap-ms = <300>;
            require-prior-idle-ms = <50>;
            hold-trigger-key-positions = <POS_RH_T3 POS_RH_T2 POS_RH_T1 POS_RH_C1R1 POS_RH_C2R1 POS_RH_C3R1 POS_RH_C4R1 POS_RH_C5R1 POS_RH_C1R2 POS_RH_C2R2 POS_RH_C3R2 POS_RH_C4R2 POS_RH_C5R2 POS_RH_C1R3 POS_RH_C2R3 POS_RH_C3R3 POS_RH_C4R3 POS_RH_C5R3 POS_RH_C1R4 POS_RH_C2R4 POS_RH_C3R4 POS_RH_C4R4 POS_RH_C5R4 POS_RH_C2R5 POS_RH_C3R5 POS_RH_C4R5 POS_RH_C6R1 POS_RH_C6R2 POS_RH_C6R3 POS_RH_C6R4>;
            hold-trigger-on-release;
        };

        // HRM_left_index_ring_bilateral -> &kp - &HRM_left_index_tap - TailorKey
        HRM_left_index_ringv1_TKZ: HRM_left_index_ringv1_TKZ {
            compatible = "zmk,behavior-hold-tap";
            #binding-cells = <2>;
            tapping-term-ms = <180>;
            bindings = <&kp>, <&HRM_left_index_tap_v1B_TKZ>;
            flavor = "tap-preferred";
            quick-tap-ms = <300>;
            require-prior-idle-ms = <50>;
            hold-trigger-key-positions = <POS_RH_T3 POS_RH_T2 POS_RH_T1 POS_RH_C1R1 POS_RH_C2R1 POS_RH_C3R1 POS_RH_C4R1 POS_RH_C5R1 POS_RH_C1R2 POS_RH_C2R2 POS_RH_C3R2 POS_RH_C4R2 POS_RH_C5R2 POS_RH_C1R3 POS_RH_C2R3 POS_RH_C3R3 POS_RH_C4R3 POS_RH_C5R3 POS_RH_C1R4 POS_RH_C2R4 POS_RH_C3R4 POS_RH_C4R4 POS_RH_C5R4 POS_RH_C2R5 POS_RH_C3R5 POS_RH_C4R5 POS_RH_C6R1 POS_RH_C6R2 POS_RH_C6R3 POS_RH_C6R4>;
            hold-trigger-on-release;
        };

        // HRM_left_index_bilateral -> &HRM_left_index_hold -> &kp - TailorKey
        HRM_left_index_v1B_TKZ: HRM_left_index_v1B_TKZ {
            compatible = "zmk,behavior-hold-tap";
            #binding-cells = <2>;
            tapping-term-ms = <180>;
            bindings = <&HRM_left_index_hold_v1B_TKZ>, <&kp>;
            flavor = "tap-preferred";
            quick-tap-ms = <300>;
            require-prior-idle-ms = <50>;
            hold-trigger-key-positions = <POS_RH_T3 POS_RH_T2 POS_RH_T1 POS_RH_C1R1 POS_RH_C2R1 POS_RH_C3R1 POS_RH_C4R1 POS_RH_C5R1 POS_RH_C1R2 POS_RH_C2R2 POS_RH_C3R2 POS_RH_C4R2 POS_RH_C5R2 POS_RH_C1R3 POS_RH_C2R3 POS_RH_C3R3 POS_RH_C4R3 POS_RH_C5R3 POS_RH_C1R4 POS_RH_C2R4 POS_RH_C3R4 POS_RH_C4R4 POS_RH_C5R4 POS_RH_C2R5 POS_RH_C3R5 POS_RH_C4R5 POS_RH_C6R1 POS_RH_C6R2 POS_RH_C6R3 POS_RH_C6R4>;
            hold-trigger-on-release;
        };

        // HRM_left_middy_index_bilateral  -> &kp ->&HRM_left_middy_tap - TailorKey
        HRM_left_middy_index_v1B_TKZ: HRM_left_middy_index_v1B_TKZ {
            compatible = "zmk,behavior-hold-tap";
            #binding-cells = <2>;
            tapping-term-ms = <210>;
            bindings = <&kp>, <&HRM_left_middy_tap_v1B_TKZ>;
            flavor = "tap-preferred";
            quick-tap-ms = <300>;
            require-prior-idle-ms = <150>;
            hold-trigger-key-positions = <POS_RH_T3 POS_RH_T2 POS_RH_T1 POS_RH_C1R1 POS_RH_C2R1 POS_RH_C3R1 POS_RH_C4R1 POS_RH_C5R1 POS_RH_C1R2 POS_RH_C2R2 POS_RH_C3R2 POS_RH_C4R2 POS_RH_C5R2 POS_RH_C1R3 POS_RH_C2R3 POS_RH_C3R3 POS_RH_C4R3 POS_RH_C5R3 POS_RH_C1R4 POS_RH_C2R4 POS_RH_C3R4 POS_RH_C4R4 POS_RH_C5R4 POS_RH_C2R5 POS_RH_C3R5 POS_RH_C4R5 POS_RH_C6R1 POS_RH_C6R2 POS_RH_C6R3 POS_RH_C6R4>;
            hold-trigger-on-release;
        };

        // HRM_left_middy_pinky_bilateral -> &kp - &HRM_left_pinky_tap - TailorKey
        HRM_left_middy_pinky_v1B_TKZ: HRM_left_middy_pinky_v1B_TKZ {
            compatible = "zmk,behavior-hold-tap";
            #binding-cells = <2>;
            tapping-term-ms = <210>;
            bindings = <&kp>, <&HRM_left_middy_tap_v1B_TKZ>;
            flavor = "tap-preferred";
            quick-tap-ms = <300>;
            require-prior-idle-ms = <150>;
            hold-trigger-key-positions = <POS_RH_T3 POS_RH_T2 POS_RH_T1 POS_RH_C1R1 POS_RH_C2R1 POS_RH_C3R1 POS_RH_C4R1 POS_RH_C5R1 POS_RH_C1R2 POS_RH_C2R2 POS_RH_C3R2 POS_RH_C4R2 POS_RH_C5R2 POS_RH_C1R3 POS_RH_C2R3 POS_RH_C3R3 POS_RH_C4R3 POS_RH_C5R3 POS_RH_C1R4 POS_RH_C2R4 POS_RH_C3R4 POS_RH_C4R4 POS_RH_C5R4 POS_RH_C2R5 POS_RH_C3R5 POS_RH_C4R5 POS_RH_C6R1 POS_RH_C6R2 POS_RH_C6R3 POS_RH_C6R4>;
            hold-trigger-on-release;
        };

        // HRM_left_middy_ring_bilateral -> &kp - &HRM_left_middy_tap - TailorKey
        HRM_left_middy_ring_v1B_TKZ: HRM_left_middy_ring_v1B_TKZ {
            compatible = "zmk,behavior-hold-tap";
            #binding-cells = <2>;
            tapping-term-ms = <210>;
            bindings = <&kp>, <&HRM_left_middy_tap_v1B_TKZ>;
            flavor = "tap-preferred";
            quick-tap-ms = <300>;
            require-prior-idle-ms = <150>;
            hold-trigger-key-positions = <POS_RH_T3 POS_RH_T2 POS_RH_T1 POS_RH_C1R1 POS_RH_C2R1 POS_RH_C3R1 POS_RH_C4R1 POS_RH_C5R1 POS_RH_C1R2 POS_RH_C2R2 POS_RH_C3R2 POS_RH_C4R2 POS_RH_C5R2 POS_RH_C1R3 POS_RH_C2R3 POS_RH_C3R3 POS_RH_C4R3 POS_RH_C5R3 POS_RH_C1R4 POS_RH_C2R4 POS_RH_C3R4 POS_RH_C4R4 POS_RH_C5R4 POS_RH_C2R5 POS_RH_C3R5 POS_RH_C4R5 POS_RH_C6R1 POS_RH_C6R2 POS_RH_C6R3 POS_RH_C6R4>;
            hold-trigger-on-release;
        };

        // HRM_left_middy_bilateral -> &HRM_left_index_hold -> &kp - TailorKey
        HRM_left_middy_v1B_TKZ: HRM_left_middy_v1B_TKZ {
            compatible = "zmk,behavior-hold-tap";
            #binding-cells = <2>;
            tapping-term-ms = <210>;
            bindings = <&HRM_left_middy_hold_v1B_TKZ>, <&kp>;
            flavor = "tap-preferred";
            quick-tap-ms = <300>;
            require-prior-idle-ms = <150>;
            hold-trigger-key-positions = <POS_RH_T3 POS_RH_T2 POS_RH_T1 POS_RH_C1R1 POS_RH_C2R1 POS_RH_C3R1 POS_RH_C4R1 POS_RH_C5R1 POS_RH_C1R2 POS_RH_C2R2 POS_RH_C3R2 POS_RH_C4R2 POS_RH_C5R2 POS_RH_C1R3 POS_RH_C2R3 POS_RH_C3R3 POS_RH_C4R3 POS_RH_C5R3 POS_RH_C1R4 POS_RH_C2R4 POS_RH_C3R4 POS_RH_C4R4 POS_RH_C5R4 POS_RH_C2R5 POS_RH_C3R5 POS_RH_C4R5 POS_RH_C6R1 POS_RH_C6R2 POS_RH_C6R3 POS_RH_C6R4>;
            hold-trigger-on-release;
        };

        // HRM_left_pinky_index_bilateral  -> &kp ->&HRM_left_pinky_tap - TailorKey
        HRM_left_pinky_index_v1B_TKZ: HRM_left_pinky_index_v1B_TKZ {
            compatible = "zmk,behavior-hold-tap";
            #binding-cells = <2>;
            tapping-term-ms = <270>;
            bindings = <&kp>, <&HRM_left_pinky_tap_v1B_TKZ>;
            flavor = "tap-preferred";
            quick-tap-ms = <300>;
            require-prior-idle-ms = <150>;
            hold-trigger-key-positions = <POS_RH_T3 POS_RH_T2 POS_RH_T1 POS_RH_C1R1 POS_RH_C2R1 POS_RH_C3R1 POS_RH_C4R1 POS_RH_C5R1 POS_RH_C1R2 POS_RH_C2R2 POS_RH_C3R2 POS_RH_C4R2 POS_RH_C5R2 POS_RH_C1R3 POS_RH_C2R3 POS_RH_C3R3 POS_RH_C4R3 POS_RH_C5R3 POS_RH_C1R4 POS_RH_C2R4 POS_RH_C3R4 POS_RH_C4R4 POS_RH_C5R4 POS_RH_C2R5 POS_RH_C3R5 POS_RH_C4R5 POS_RH_C6R1 POS_RH_C6R2 POS_RH_C6R3 POS_RH_C6R4>;
            hold-trigger-on-release;
        };

        // HRM_left_pinky_middy_bilateral -> &kp - &HRM_left_pinky_tap - TailorKey
        HRM_left_pinky_middy_v1B_TKZ: HRM_left_pinky_middy_v1B_TKZ {
            compatible = "zmk,behavior-hold-tap";
            #binding-cells = <2>;
            tapping-term-ms = <270>;
            bindings = <&kp>, <&HRM_left_pinky_tap_v1B_TKZ>;
            flavor = "tap-preferred";
            quick-tap-ms = <300>;
            require-prior-idle-ms = <150>;
            hold-trigger-key-positions = <POS_RH_T3 POS_RH_T2 POS_RH_T1 POS_RH_C1R1 POS_RH_C2R1 POS_RH_C3R1 POS_RH_C4R1 POS_RH_C5R1 POS_RH_C1R2 POS_RH_C2R2 POS_RH_C3R2 POS_RH_C4R2 POS_RH_C5R2 POS_RH_C1R3 POS_RH_C2R3 POS_RH_C3R3 POS_RH_C4R3 POS_RH_C5R3 POS_RH_C1R4 POS_RH_C2R4 POS_RH_C3R4 POS_RH_C4R4 POS_RH_C5R4 POS_RH_C2R5 POS_RH_C3R5 POS_RH_C4R5 POS_RH_C6R1 POS_RH_C6R2 POS_RH_C6R3 POS_RH_C6R4>;
            hold-trigger-on-release;
        };

        // HRM_left_pinky_ring_bilateral -> &kp - &HRM_left_pinky_tap - TailorKey
        HRM_left_pinky_ring_v1B_TKZ: HRM_left_pinky_ring_v1B_TKZ {
            compatible = "zmk,behavior-hold-tap";
            #binding-cells = <2>;
            tapping-term-ms = <270>;
            bindings = <&kp>, <&HRM_left_pinky_tap_v1B_TKZ>;
            flavor = "tap-preferred";
            quick-tap-ms = <300>;
            require-prior-idle-ms = <150>;
            hold-trigger-key-positions = <POS_RH_T3 POS_RH_T2 POS_RH_T1 POS_RH_C1R1 POS_RH_C2R1 POS_RH_C3R1 POS_RH_C4R1 POS_RH_C5R1 POS_RH_C1R2 POS_RH_C2R2 POS_RH_C3R2 POS_RH_C4R2 POS_RH_C5R2 POS_RH_C1R3 POS_RH_C2R3 POS_RH_C3R3 POS_RH_C4R3 POS_RH_C5R3 POS_RH_C1R4 POS_RH_C2R4 POS_RH_C3R4 POS_RH_C4R4 POS_RH_C5R4 POS_RH_C2R5 POS_RH_C3R5 POS_RH_C4R5 POS_RH_C6R1 POS_RH_C6R2 POS_RH_C6R3 POS_RH_C6R4>;
            hold-trigger-on-release;
        };

        // HRM_left_pinky_bilateral  - &HRM_left_pinky_hold -> &kp - TailorKey
        HRM_left_pinky_v1B_TKZ: HRM_left_pinky_v1B_TKZ {
            compatible = "zmk,behavior-hold-tap";
            #binding-cells = <2>;
            tapping-term-ms = <270>;
            bindings = <&HRM_left_pinky_hold_v1B_TKZ>, <&kp>;
            flavor = "tap-preferred";
            quick-tap-ms = <300>;
            require-prior-idle-ms = <150>;
            hold-trigger-key-positions = <POS_RH_T3 POS_RH_T2 POS_RH_T1 POS_RH_C1R1 POS_RH_C2R1 POS_RH_C3R1 POS_RH_C4R1 POS_RH_C5R1 POS_RH_C1R2 POS_RH_C2R2 POS_RH_C3R2 POS_RH_C4R2 POS_RH_C5R2 POS_RH_C1R3 POS_RH_C2R3 POS_RH_C3R3 POS_RH_C4R3 POS_RH_C5R3 POS_RH_C1R4 POS_RH_C2R4 POS_RH_C3R4 POS_RH_C4R4 POS_RH_C5R4 POS_RH_C2R5 POS_RH_C3R5 POS_RH_C4R5 POS_RH_C6R1 POS_RH_C6R2 POS_RH_C6R3 POS_RH_C6R4>;
            hold-trigger-on-release;
        };

        // HRM_left_ring_index_bilateral  -> &kp ->&HRM_left_ring_tap - TailorKey
        HRM_left_ring_index_v1B_TKZ: HRM_left_ring_index_v1B_TKZ {
            compatible = "zmk,behavior-hold-tap";
            #binding-cells = <2>;
            tapping-term-ms = <240>;
            bindings = <&kp>, <&HRM_left_ring_tap_v1B_TKZ>;
            flavor = "tap-preferred";
            quick-tap-ms = <300>;
            require-prior-idle-ms = <150>;
            hold-trigger-key-positions = <POS_RH_T3 POS_RH_T2 POS_RH_T1 POS_RH_C1R1 POS_RH_C2R1 POS_RH_C3R1 POS_RH_C4R1 POS_RH_C5R1 POS_RH_C1R2 POS_RH_C2R2 POS_RH_C3R2 POS_RH_C4R2 POS_RH_C5R2 POS_RH_C1R3 POS_RH_C2R3 POS_RH_C3R3 POS_RH_C4R3 POS_RH_C5R3 POS_RH_C1R4 POS_RH_C2R4 POS_RH_C3R4 POS_RH_C4R4 POS_RH_C5R4 POS_RH_C2R5 POS_RH_C3R5 POS_RH_C4R5 POS_RH_C6R1 POS_RH_C6R2 POS_RH_C6R3 POS_RH_C6R4>;
            hold-trigger-on-release;
        };

        // HRM_left_ring_middy_bilateral -> &kp - &HRM_left_ring_tap - TailorKey
        HRM_left_ring_middy_v1B_TKZ: HRM_left_ring_middy_v1B_TKZ {
            compatible = "zmk,behavior-hold-tap";
            #binding-cells = <2>;
            tapping-term-ms = <240>;
            bindings = <&kp>, <&HRM_left_ring_tap_v1B_TKZ>;
            flavor = "tap-preferred";
            quick-tap-ms = <300>;
            require-prior-idle-ms = <150>;
            hold-trigger-key-positions = <POS_RH_T3 POS_RH_T2 POS_RH_T1 POS_RH_C1R1 POS_RH_C2R1 POS_RH_C3R1 POS_RH_C4R1 POS_RH_C5R1 POS_RH_C1R2 POS_RH_C2R2 POS_RH_C3R2 POS_RH_C4R2 POS_RH_C5R2 POS_RH_C1R3 POS_RH_C2R3 POS_RH_C3R3 POS_RH_C4R3 POS_RH_C5R3 POS_RH_C1R4 POS_RH_C2R4 POS_RH_C3R4 POS_RH_C4R4 POS_RH_C5R4 POS_RH_C2R5 POS_RH_C3R5 POS_RH_C4R5 POS_RH_C6R1 POS_RH_C6R2 POS_RH_C6R3 POS_RH_C6R4>;
            hold-trigger-on-release;
        };

        // HRM_left_ring_pinky_bilateral -> &kp - &HRM_left_ring_tap - TailorKey
        HRM_left_ring_pinky_v1B_TKZ: HRM_left_ring_pinky_v1B_TKZ {
            compatible = "zmk,behavior-hold-tap";
            #binding-cells = <2>;
            tapping-term-ms = <240>;
            bindings = <&kp>, <&HRM_left_ring_tap_v1B_TKZ>;
            flavor = "tap-preferred";
            quick-tap-ms = <300>;
            require-prior-idle-ms = <150>;
            hold-trigger-key-positions = <POS_RH_T3 POS_RH_T2 POS_RH_T1 POS_RH_C1R1 POS_RH_C2R1 POS_RH_C3R1 POS_RH_C4R1 POS_RH_C5R1 POS_RH_C1R2 POS_RH_C2R2 POS_RH_C3R2 POS_RH_C4R2 POS_RH_C5R2 POS_RH_C1R3 POS_RH_C2R3 POS_RH_C3R3 POS_RH_C4R3 POS_RH_C5R3 POS_RH_C1R4 POS_RH_C2R4 POS_RH_C3R4 POS_RH_C4R4 POS_RH_C5R4 POS_RH_C2R5 POS_RH_C3R5 POS_RH_C4R5 POS_RH_C6R1 POS_RH_C6R2 POS_RH_C6R3 POS_RH_C6R4>;
            hold-trigger-on-release;
        };

        // HRM_left_ring_bilateral  - &HRM_left_ring_hold -> &kp - TailorKey
        HRM_left_ring_v1B_TKZ: HRM_left_ring_v1B_TKZ {
            compatible = "zmk,behavior-hold-tap";
            #binding-cells = <2>;
            tapping-term-ms = <240>;
            bindings = <&HRM_left_ring_hold_v1B_TKZ>, <&kp>;
            flavor = "tap-preferred";
            quick-tap-ms = <300>;
            require-prior-idle-ms = <150>;
            hold-trigger-key-positions = <POS_RH_T3 POS_RH_T2 POS_RH_T1 POS_RH_C1R1 POS_RH_C2R1 POS_RH_C3R1 POS_RH_C4R1 POS_RH_C5R1 POS_RH_C1R2 POS_RH_C2R2 POS_RH_C3R2 POS_RH_C4R2 POS_RH_C5R2 POS_RH_C1R3 POS_RH_C2R3 POS_RH_C3R3 POS_RH_C4R3 POS_RH_C5R3 POS_RH_C1R4 POS_RH_C2R4 POS_RH_C3R4 POS_RH_C4R4 POS_RH_C5R4 POS_RH_C2R5 POS_RH_C3R5 POS_RH_C4R5 POS_RH_C6R1 POS_RH_C6R2 POS_RH_C6R3 POS_RH_C6R4>;
            hold-trigger-on-release;
        };

        // HRM_right_index_middy_bilateral -> &kp - &HRM_right_index_tap - TailorKey
        HRM_right_index_middy_v1B_TKZ: HRM_right_index_middy_v1B_TKZ {
            compatible = "zmk,behavior-hold-tap";
            #binding-cells = <2>;
            tapping-term-ms = <180>;
            bindings = <&kp>, <&HRM_right_index_tap_v1B_TKZ>;
            flavor = "tap-preferred";
            quick-tap-ms = <300>;
            require-prior-idle-ms = <50>;
            hold-trigger-key-positions = <POS_LH_C6R1 POS_LH_C6R2 POS_LH_C6R3 POS_LH_C6R4 POS_LH_C5R4 POS_LH_C5R3 POS_LH_C5R2 POS_LH_C4R1 POS_LH_C5R1 POS_LH_C4R2 POS_LH_C4R3 POS_LH_C4R4 POS_LH_C4R5 POS_LH_C3R5 POS_LH_C3R4 POS_LH_C3R3 POS_LH_C3R2 POS_LH_C3R1 POS_LH_C2R1 POS_LH_C1R1 POS_LH_C1R2 POS_LH_C2R2 POS_LH_C2R3 POS_LH_C1R3 POS_LH_C1R4 POS_LH_C2R4 POS_LH_C2R5 POS_LH_T3 POS_LH_T2 POS_LH_T1>;
            hold-trigger-on-release;
        };

        // HRM_right_index_pinky_bilateral -> &kp - &HRM_right_index_tap - TailorKey
        HRM_right_index_pinky_v1B_TKZ: HRM_right_index_pinky_v1B_TKZ {
            compatible = "zmk,behavior-hold-tap";
            #binding-cells = <2>;
            tapping-term-ms = <180>;
            bindings = <&kp>, <&HRM_right_index_tap_v1B_TKZ>;
            flavor = "tap-preferred";
            quick-tap-ms = <300>;
            require-prior-idle-ms = <50>;
            hold-trigger-key-positions = <POS_LH_C6R1 POS_LH_C6R2 POS_LH_C6R3 POS_LH_C6R4 POS_LH_C5R4 POS_LH_C5R3 POS_LH_C5R2 POS_LH_C4R1 POS_LH_C5R1 POS_LH_C4R2 POS_LH_C4R3 POS_LH_C4R4 POS_LH_C4R5 POS_LH_C3R5 POS_LH_C3R4 POS_LH_C3R3 POS_LH_C3R2 POS_LH_C3R1 POS_LH_C2R1 POS_LH_C1R1 POS_LH_C1R2 POS_LH_C2R2 POS_LH_C2R3 POS_LH_C1R3 POS_LH_C1R4 POS_LH_C2R4 POS_LH_C2R5 POS_LH_T3 POS_LH_T2 POS_LH_T1>;
            hold-trigger-on-release;
        };

        // HRM_right_index_ring_bilateral -> &kp - &HRM_right_index_tap - TailorKey
        HRM_right_index_ring_v1B_TKZ: HRM_right_index_ring_v1B_TKZ {
            compatible = "zmk,behavior-hold-tap";
            #binding-cells = <2>;
            tapping-term-ms = <180>;
            bindings = <&kp>, <&HRM_right_index_tap_v1B_TKZ>;
            flavor = "tap-preferred";
            quick-tap-ms = <300>;
            require-prior-idle-ms = <50>;
            hold-trigger-key-positions = <POS_LH_C6R1 POS_LH_C6R2 POS_LH_C6R3 POS_LH_C6R4 POS_LH_C5R4 POS_LH_C5R3 POS_LH_C5R2 POS_LH_C4R1 POS_LH_C5R1 POS_LH_C4R2 POS_LH_C4R3 POS_LH_C4R4 POS_LH_C4R5 POS_LH_C3R5 POS_LH_C3R4 POS_LH_C3R3 POS_LH_C3R2 POS_LH_C3R1 POS_LH_C2R1 POS_LH_C1R1 POS_LH_C1R2 POS_LH_C2R2 POS_LH_C2R3 POS_LH_C1R3 POS_LH_C1R4 POS_LH_C2R4 POS_LH_C2R5 POS_LH_T3 POS_LH_T2 POS_LH_T1>;
            hold-trigger-on-release;
        };

        // HRM_right_index_bilateral -> &HRM_right_index_hold -> &kp - TailorKey
        HRM_right_index_v1B_TKZ: HRM_right_index_v1B_TKZ {
            compatible = "zmk,behavior-hold-tap";
            #binding-cells = <2>;
            tapping-term-ms = <180>;
            bindings = <&HRM_right_index_hold_v1B_TKZ>, <&kp>;
            flavor = "tap-preferred";
            quick-tap-ms = <300>;
            require-prior-idle-ms = <50>;
            hold-trigger-key-positions = <POS_LH_C6R1 POS_LH_C6R2 POS_LH_C6R3 POS_LH_C6R4 POS_LH_C5R4 POS_LH_C5R3 POS_LH_C5R2 POS_LH_C4R1 POS_LH_C5R1 POS_LH_C4R2 POS_LH_C4R3 POS_LH_C4R4 POS_LH_C4R5 POS_LH_C3R5 POS_LH_C3R4 POS_LH_C3R3 POS_LH_C3R2 POS_LH_C3R1 POS_LH_C2R1 POS_LH_C1R1 POS_LH_C1R2 POS_LH_C2R2 POS_LH_C2R3 POS_LH_C1R3 POS_LH_C1R4 POS_LH_C2R4 POS_LH_C2R5 POS_LH_T3 POS_LH_T2 POS_LH_T1>;
            hold-trigger-on-release;
        };

        // HRM_right_middy_index_bilateral  -> &kp ->&HRM_right_middy_tap - TailorKey
        HRM_right_middy_index_v1B_TKZ: HRM_right_middy_index_v1B_TKZ {
            compatible = "zmk,behavior-hold-tap";
            #binding-cells = <2>;
            tapping-term-ms = <210>;
            bindings = <&kp>, <&HRM_right_middy_tap_v1B_TKZ>;
            flavor = "tap-preferred";
            quick-tap-ms = <300>;
            require-prior-idle-ms = <150>;
            hold-trigger-key-positions = <POS_LH_C6R1 POS_LH_C6R2 POS_LH_C6R3 POS_LH_C6R4 POS_LH_C5R4 POS_LH_C5R3 POS_LH_C5R2 POS_LH_C4R1 POS_LH_C5R1 POS_LH_C4R2 POS_LH_C4R3 POS_LH_C4R4 POS_LH_C4R5 POS_LH_C3R5 POS_LH_C3R4 POS_LH_C3R3 POS_LH_C3R2 POS_LH_C3R1 POS_LH_C2R1 POS_LH_C1R1 POS_LH_C1R2 POS_LH_C2R2 POS_LH_C2R3 POS_LH_C1R3 POS_LH_C1R4 POS_LH_C2R4 POS_LH_C2R5 POS_LH_T3 POS_LH_T2 POS_LH_T1>;
            hold-trigger-on-release;
        };

        // HRM_right_middy_pinky_bilateral -> &kp - &HRM_right_pinky_tap - TailorKey
        HRM_right_middy_pinky_v1B_TKZ: HRM_right_middy_pinky_v1B_TKZ {
            compatible = "zmk,behavior-hold-tap";
            #binding-cells = <2>;
            tapping-term-ms = <210>;
            bindings = <&kp>, <&HRM_right_middy_tap_v1B_TKZ>;
            flavor = "tap-preferred";
            quick-tap-ms = <300>;
            require-prior-idle-ms = <150>;
            hold-trigger-key-positions = <POS_LH_C6R1 POS_LH_C6R2 POS_LH_C6R4 POS_LH_C5R4 POS_LH_C1R4 POS_LH_C1R3 POS_LH_C1R2 POS_LH_C1R1 POS_LH_C5R1 POS_LH_C5R2 POS_LH_C5R3 POS_LH_C6R3 POS_LH_C4R4 POS_LH_C4R5 POS_LH_T1 POS_LH_T2 POS_LH_T3 POS_LH_C2R5 POS_LH_C3R5 POS_LH_C3R4 POS_LH_C2R4 POS_LH_C2R3 POS_LH_C2R2 POS_LH_C2R1 POS_LH_C3R1 POS_LH_C3R2 POS_LH_C3R3 POS_LH_C4R2 POS_LH_C4R1 POS_LH_C4R3>;
            hold-trigger-on-release;
        };

        // HRM_right_middy_ring_bilateral -> &kp - &HRM_right_middy_tap - TailorKey
        HRM_right_middy_ring_v1B_TKZ: HRM_right_middy_ring_v1B_TKZ {
            compatible = "zmk,behavior-hold-tap";
            #binding-cells = <2>;
            tapping-term-ms = <210>;
            bindings = <&kp>, <&HRM_right_middy_tap_v1B_TKZ>;
            flavor = "tap-preferred";
            quick-tap-ms = <300>;
            require-prior-idle-ms = <150>;
            hold-trigger-key-positions = <POS_LH_C6R1 POS_LH_C6R2 POS_LH_C6R3 POS_LH_C6R4 POS_LH_C5R4 POS_LH_C5R3 POS_LH_C5R2 POS_LH_C4R1 POS_LH_C5R1 POS_LH_C4R2 POS_LH_C4R3 POS_LH_C4R4 POS_LH_C4R5 POS_LH_C3R5 POS_LH_C3R4 POS_LH_C3R3 POS_LH_C3R2 POS_LH_C3R1 POS_LH_C2R1 POS_LH_C1R1 POS_LH_C1R2 POS_LH_C2R2 POS_LH_C2R3 POS_LH_C1R3 POS_LH_C1R4 POS_LH_C2R4 POS_LH_C2R5 POS_LH_T3 POS_LH_T2 POS_LH_T1>;
            hold-trigger-on-release;
        };

        // HRM_right_middy_bilateral -> &HRM_right_index_hold -> &kp - TailorKey
        HRM_right_middy_v1B_TKZ: HRM_right_middy_v1B_TKZ {
            compatible = "zmk,behavior-hold-tap";
            #binding-cells = <2>;
            tapping-term-ms = <210>;
            bindings = <&HRM_right_middy_hold_v1B_TKZ>, <&kp>;
            flavor = "tap-preferred";
            quick-tap-ms = <300>;
            require-prior-idle-ms = <150>;
            hold-trigger-key-positions = <POS_LH_C6R1 POS_LH_C6R2 POS_LH_C6R3 POS_LH_C6R4 POS_LH_C5R4 POS_LH_C5R3 POS_LH_C5R2 POS_LH_C4R1 POS_LH_C5R1 POS_LH_C4R2 POS_LH_C4R3 POS_LH_C4R4 POS_LH_C4R5 POS_LH_C3R5 POS_LH_C3R4 POS_LH_C3R3 POS_LH_C3R2 POS_LH_C3R1 POS_LH_C2R1 POS_LH_C1R1 POS_LH_C1R2 POS_LH_C2R2 POS_LH_C2R3 POS_LH_C1R3 POS_LH_C1R4 POS_LH_C2R4 POS_LH_C2R5 POS_LH_T3 POS_LH_T2 POS_LH_T1>;
            hold-trigger-on-release;
        };

        // HRM_right_pinky_index_bilateral  -> &kp ->&HRM_right_pinky_tap - TailorKey
        HRM_right_pinky_index_v1B_TKZ: HRM_right_pinky_index_v1B_TKZ {
            compatible = "zmk,behavior-hold-tap";
            #binding-cells = <2>;
            tapping-term-ms = <270>;
            bindings = <&kp>, <&HRM_right_pinky_tap_v1B_TKZ>;
            flavor = "tap-preferred";
            quick-tap-ms = <300>;
            require-prior-idle-ms = <150>;
            hold-trigger-key-positions = <POS_LH_C6R1 POS_LH_C6R2 POS_LH_C6R3 POS_LH_C6R4 POS_LH_C5R4 POS_LH_C5R3 POS_LH_C5R2 POS_LH_C4R1 POS_LH_C5R1 POS_LH_C4R2 POS_LH_C4R3 POS_LH_C4R4 POS_LH_C4R5 POS_LH_C3R5 POS_LH_C3R4 POS_LH_C3R3 POS_LH_C3R2 POS_LH_C3R1 POS_LH_C2R1 POS_LH_C1R1 POS_LH_C1R2 POS_LH_C2R2 POS_LH_C2R3 POS_LH_C1R3 POS_LH_C1R4 POS_LH_C2R4 POS_LH_C2R5 POS_LH_T3 POS_LH_T2 POS_LH_T1>;
            hold-trigger-on-release;
        };

        // HRM_right_pinky_middy_bilateral -> &kp - &HRM_right_pinky_tap - TailorKey
        HRM_right_pinky_middy_v1B_TKZ: HRM_right_pinky_middy_v1B_TKZ {
            compatible = "zmk,behavior-hold-tap";
            #binding-cells = <2>;
            tapping-term-ms = <270>;
            bindings = <&kp>, <&HRM_right_pinky_tap_v1B_TKZ>;
            flavor = "tap-preferred";
            quick-tap-ms = <300>;
            require-prior-idle-ms = <150>;
            hold-trigger-key-positions = <POS_LH_C6R1 POS_LH_C6R2 POS_LH_C6R3 POS_LH_C6R4 POS_LH_C5R4 POS_LH_C5R3 POS_LH_C5R2 POS_LH_C4R1 POS_LH_C5R1 POS_LH_C4R2 POS_LH_C4R3 POS_LH_C4R4 POS_LH_C4R5 POS_LH_C3R5 POS_LH_C3R4 POS_LH_C3R3 POS_LH_C3R2 POS_LH_C3R1 POS_LH_C2R1 POS_LH_C1R1 POS_LH_C1R2 POS_LH_C2R2 POS_LH_C2R3 POS_LH_C1R3 POS_LH_C1R4 POS_LH_C2R4 POS_LH_C2R5 POS_LH_T3 POS_LH_T2 POS_LH_T1>;
            hold-trigger-on-release;
        };

        // HRM_right_pinky_ring_bilateral -> &kp - &HRM_right_pinky_tap - TailorKey
        HRM_right_pinky_ring_v1B_TKZ: HRM_right_pinky_ring_v1B_TKZ {
            compatible = "zmk,behavior-hold-tap";
            #binding-cells = <2>;
            tapping-term-ms = <270>;
            bindings = <&kp>, <&HRM_right_pinky_tap_v1B_TKZ>;
            flavor = "tap-preferred";
            quick-tap-ms = <300>;
            require-prior-idle-ms = <150>;
            hold-trigger-key-positions = <POS_LH_C6R1 POS_LH_C6R2 POS_LH_C6R3 POS_LH_C6R4 POS_LH_C5R4 POS_LH_C5R3 POS_LH_C5R2 POS_LH_C4R1 POS_LH_C5R1 POS_LH_C4R2 POS_LH_C4R3 POS_LH_C4R4 POS_LH_C4R5 POS_LH_C3R5 POS_LH_C3R4 POS_LH_C3R3 POS_LH_C3R2 POS_LH_C3R1 POS_LH_C2R1 POS_LH_C1R1 POS_LH_C1R2 POS_LH_C2R2 POS_LH_C2R3 POS_LH_C1R3 POS_LH_C1R4 POS_LH_C2R4 POS_LH_C2R5 POS_LH_T3 POS_LH_T2 POS_LH_T1>;
            hold-trigger-on-release;
        };

        // HRM_right_pinky_bilateral  - &HRM_right_pinky_hold -> &kp - TailorKey
        HRM_right_pinky_v1B_TKZ: HRM_right_pinky_v1B_TKZ {
            compatible = "zmk,behavior-hold-tap";
            #binding-cells = <2>;
            tapping-term-ms = <270>;
            bindings = <&HRM_right_pinky_hold_v1B_TKZ>, <&kp>;
            flavor = "tap-preferred";
            quick-tap-ms = <300>;
            require-prior-idle-ms = <150>;
            hold-trigger-key-positions = <POS_LH_C6R1 POS_LH_C6R2 POS_LH_C6R3 POS_LH_C6R4 POS_LH_C5R4 POS_LH_C5R3 POS_LH_C5R2 POS_LH_C4R1 POS_LH_C5R1 POS_LH_C4R2 POS_LH_C4R3 POS_LH_C4R4 POS_LH_C4R5 POS_LH_C3R5 POS_LH_C3R4 POS_LH_C3R3 POS_LH_C3R2 POS_LH_C3R1 POS_LH_C2R1 POS_LH_C1R1 POS_LH_C1R2 POS_LH_C2R2 POS_LH_C2R3 POS_LH_C1R3 POS_LH_C1R4 POS_LH_C2R4 POS_LH_C2R5 POS_LH_T3 POS_LH_T2 POS_LH_T1>;
            hold-trigger-on-release;
        };

        // HRM_right_ring_index_bilateral  -> &kp ->&HRM_right_ring_tap - TailorKey
        HRM_right_ring_index_v1B_TKZ: HRM_right_ring_index_v1B_TKZ {
            compatible = "zmk,behavior-hold-tap";
            #binding-cells = <2>;
            tapping-term-ms = <240>;
            bindings = <&kp>, <&HRM_right_ring_tap_v1B_TKZ>;
            flavor = "tap-preferred";
            quick-tap-ms = <300>;
            require-prior-idle-ms = <150>;
            hold-trigger-key-positions = <POS_LH_C6R1 POS_LH_C6R2 POS_LH_C6R3 POS_LH_C6R4 POS_LH_C5R4 POS_LH_C5R3 POS_LH_C5R2 POS_LH_C4R1 POS_LH_C5R1 POS_LH_C4R2 POS_LH_C4R3 POS_LH_C4R4 POS_LH_C4R5 POS_LH_C3R5 POS_LH_C3R4 POS_LH_C3R3 POS_LH_C3R2 POS_LH_C3R1 POS_LH_C2R1 POS_LH_C1R1 POS_LH_C1R2 POS_LH_C2R2 POS_LH_C2R3 POS_LH_C1R3 POS_LH_C1R4 POS_LH_C2R4 POS_LH_C2R5 POS_LH_T3 POS_LH_T2 POS_LH_T1>;
            hold-trigger-on-release;
        };

        // HRM_right_ring_middy_bilateral -> &kp - &HRM_right_ring_tap - TailorKey
        HRM_right_ring_middy_v1B_TKZ: HRM_right_ring_middy_v1B_TKZ {
            compatible = "zmk,behavior-hold-tap";
            #binding-cells = <2>;
            tapping-term-ms = <240>;
            bindings = <&kp>, <&HRM_right_ring_tap_v1B_TKZ>;
            flavor = "tap-preferred";
            quick-tap-ms = <300>;
            require-prior-idle-ms = <150>;
            hold-trigger-key-positions = <POS_LH_C6R1 POS_LH_C6R2 POS_LH_C6R3 POS_LH_C6R4 POS_LH_C5R4 POS_LH_C5R3 POS_LH_C5R2 POS_LH_C4R1 POS_LH_C5R1 POS_LH_C4R2 POS_LH_C4R3 POS_LH_C4R4 POS_LH_C4R5 POS_LH_C3R5 POS_LH_C3R4 POS_LH_C3R3 POS_LH_C3R2 POS_LH_C3R1 POS_LH_C2R1 POS_LH_C1R1 POS_LH_C1R2 POS_LH_C2R2 POS_LH_C2R3 POS_LH_C1R3 POS_LH_C1R4 POS_LH_C2R4 POS_LH_C2R5 POS_LH_T3 POS_LH_T2 POS_LH_T1>;
            hold-trigger-on-release;
        };

        // HRM_right_ring_pinky_bilateral -> &kp - &HRM_right_ring_tap - TailorKey
        HRM_right_ring_pinky_v1B_TKZ: HRM_right_ring_pinky_v1B_TKZ {
            compatible = "zmk,behavior-hold-tap";
            #binding-cells = <2>;
            tapping-term-ms = <240>;
            bindings = <&kp>, <&HRM_right_ring_tap_v1B_TKZ>;
            flavor = "tap-preferred";
            quick-tap-ms = <300>;
            require-prior-idle-ms = <150>;
            hold-trigger-key-positions = <POS_LH_C6R1 POS_LH_C6R2 POS_LH_C6R3 POS_LH_C6R4 POS_LH_C5R4 POS_LH_C5R3 POS_LH_C5R2 POS_LH_C4R1 POS_LH_C5R1 POS_LH_C4R2 POS_LH_C4R3 POS_LH_C4R4 POS_LH_C4R5 POS_LH_C3R5 POS_LH_C3R4 POS_LH_C3R3 POS_LH_C3R2 POS_LH_C3R1 POS_LH_C2R1 POS_LH_C1R1 POS_LH_C1R2 POS_LH_C2R2 POS_LH_C2R3 POS_LH_C1R3 POS_LH_C1R4 POS_LH_C2R4 POS_LH_C2R5 POS_LH_T3 POS_LH_T2 POS_LH_T1>;
            hold-trigger-on-release;
        };

        // HRM_right_ring_bilateral  - &HRM_right_ring_hold -> &kp - TailorKey
        HRM_right_ring_v1B_TKZ: HRM_right_ring_v1B_TKZ {
            compatible = "zmk,behavior-hold-tap";
            #binding-cells = <2>;
            tapping-term-ms = <240>;
            bindings = <&HRM_right_ring_hold_v1B_TKZ>, <&kp>;
            flavor = "tap-preferred";
            quick-tap-ms = <300>;
            require-prior-idle-ms = <150>;
            hold-trigger-key-positions = <POS_LH_C6R1 POS_LH_C6R2 POS_LH_C6R3 POS_LH_C6R4 POS_LH_C5R4 POS_LH_C5R3 POS_LH_C5R2 POS_LH_C4R1 POS_LH_C5R1 POS_LH_C4R2 POS_LH_C4R3 POS_LH_C4R4 POS_LH_C4R5 POS_LH_C3R5 POS_LH_C3R4 POS_LH_C3R3 POS_LH_C3R2 POS_LH_C3R1 POS_LH_C2R1 POS_LH_C1R1 POS_LH_C1R2 POS_LH_C2R2 POS_LH_C2R3 POS_LH_C1R3 POS_LH_C1R4 POS_LH_C2R4 POS_LH_C2R5 POS_LH_T3 POS_LH_T2 POS_LH_T1>;
            hold-trigger-on-release;
        };

        // space_layer_access - TailorKey
        space_v3_TKZ: space_v3_TKZ {
            compatible = "zmk,behavior-hold-tap";
            #binding-cells = <2>;
            tapping-term-ms = <200>;
            bindings = <&mo>, <&kp>;
            flavor = "balanced";
            quick-tap-ms = <150>;
            require-prior-idle-ms = <0>;
        };

        // thumb_layer_access - TailorKey
        thumb_v2_TKZ: thumb_v2_TKZ {
            compatible = "zmk,behavior-hold-tap";
            #binding-cells = <2>;
            tapping-term-ms = <200>;
            bindings = <&mo>, <&kp>;
            flavor = "balanced";
            quick-tap-ms = <300>;
            require-prior-idle-ms = <0>;
        };

        // Tap for Enter, hold to go to home layer.
        to_layer_tap: to_layer_tap {
            compatible = "zmk,behavior-hold-tap";
            #binding-cells = <2>;
            tapping-term-ms = <200>;
            bindings = <&to>, <&kp>;
            flavor = "balanced";
            quick-tap-ms = <300>;
            require-prior-idle-ms = <0>;
        };

        // Sends a different keypress, depending on whether it's held or tapped.
        //
        // If you hold the key for longer than 200ms, the first keycode is sent. If you tap the key (release before 200ms), the second keycode is sent. If you press another key within the 200ms, the default/first behavior is activated.
        mod_tap_primary_preferred: mod_tap_primary_preferred {
            compatible = "zmk,behavior-hold-tap";
            #binding-cells = <2>;
            tapping-term-ms = <200>;
            bindings = <&kp>, <&kp>;
            flavor = "tap-preferred";
            quick-tap-ms = <300>;
            require-prior-idle-ms = <0>;
        };
    };
};

/* Automatically generated combos definitions */
/ {
    combos {
        compatible = "zmk,combos";

        // toggle gaming layer - TailorKey
        combo_gaming_toggle_v1_TKZ {
            timeout-ms = <50>;
            key-positions = <POS_LH_C2R5 POS_LH_C1R4>;
            bindings = <&tog LAYER_Gaming>;
        };

        // capslock when pressing both T1's - TailorKey
        combo_capslock_v1_TKZ {
            key-positions = <POS_LH_T1 POS_RH_T1>;
            bindings = <&kp CAPS>;
            layers = <LAYER_Home LAYER_Qwerty LAYER_NoHRM>;
        };

        // F11 combo for Go60 - TailorKey
        combo_F11_cb_v1_TKZ {
            key-positions = <POS_LH_C5R1 POS_LH_C5R2>;
            bindings = <&kp F11>;
            layers = <LAYER_Home LAYER_Qwerty LAYER_LeftPinky LAYER_LeftRingy LAYER_LeftMiddy LAYER_LeftIndex LAYER_RightPinky LAYER_RightRingy LAYER_RightMiddy LAYER_RightIndex LAYER_NoHRM>;
        };

        // F12 combo for Go60 - TailorKey
        combo_F12_cb_v1_TKZ {
            key-positions = <POS_LH_C4R2 POS_LH_C4R1>;
            bindings = <&kp F12>;
            layers = <LAYER_Home LAYER_Qwerty LAYER_LeftPinky LAYER_LeftRingy LAYER_LeftMiddy LAYER_LeftIndex LAYER_RightPinky LAYER_RightRingy LAYER_RightMiddy LAYER_RightIndex LAYER_NoHRM>;
        };

        // F13 combo for Go60 - TailorKey
        combo_F13_cb_v1_TKZ {
            key-positions = <POS_LH_C3R2 POS_LH_C3R1>;
            bindings = <&kp F13>;
            layers = <LAYER_Home LAYER_Qwerty LAYER_LeftPinky LAYER_LeftRingy LAYER_LeftMiddy LAYER_LeftIndex LAYER_RightPinky LAYER_RightRingy LAYER_RightMiddy LAYER_RightIndex LAYER_NoHRM>;
        };

        // F14 combo for Go60 - TailorKey
        combo_F14_cb_v1_TKZ {
            key-positions = <POS_LH_C2R2 POS_LH_C2R1>;
            bindings = <&kp F14>;
            layers = <LAYER_Home LAYER_Qwerty LAYER_LeftPinky LAYER_LeftRingy LAYER_LeftMiddy LAYER_LeftIndex LAYER_RightPinky LAYER_RightRingy LAYER_RightMiddy LAYER_RightIndex LAYER_NoHRM>;
        };

        // F15 combo for Go60 - TailorKey
        combo_F15_cb_v1_TKZ {
            key-positions = <POS_LH_C1R2 POS_LH_C1R1>;
            bindings = <&kp F15>;
            layers = <LAYER_Home LAYER_Qwerty LAYER_LeftPinky LAYER_LeftRingy LAYER_LeftMiddy LAYER_LeftIndex LAYER_RightPinky LAYER_RightRingy LAYER_RightMiddy LAYER_RightIndex LAYER_NoHRM>;
        };

        // F16 combo for Go60 - TailorKey
        combo_F16_cb_v1_TKZ {
            key-positions = <POS_RH_C1R2 POS_RH_C1R1>;
            bindings = <&kp F16>;
            layers = <LAYER_Home LAYER_Qwerty LAYER_LeftPinky LAYER_LeftRingy LAYER_LeftMiddy LAYER_LeftIndex LAYER_RightPinky LAYER_RightRingy LAYER_RightMiddy LAYER_RightIndex LAYER_NoHRM>;
        };

        // F17 combo for Go60 - TailorKey
        combo_F17_cb_v1_TKZ {
            key-positions = <POS_RH_C2R1 POS_RH_C2R2>;
            bindings = <&kp F17>;
            layers = <LAYER_Home LAYER_Qwerty LAYER_LeftPinky LAYER_LeftRingy LAYER_LeftMiddy LAYER_LeftIndex LAYER_RightPinky LAYER_RightRingy LAYER_RightMiddy LAYER_RightIndex LAYER_NoHRM>;
        };

        // F18 combo for Go60 - TailorKey
        combo_F18_cb_v1_TKZ {
            key-positions = <POS_RH_C3R1 POS_RH_C3R2>;
            bindings = <&kp F18>;
            layers = <LAYER_Home LAYER_Qwerty LAYER_LeftPinky LAYER_LeftRingy LAYER_LeftMiddy LAYER_LeftIndex LAYER_RightPinky LAYER_RightRingy LAYER_RightMiddy LAYER_RightIndex LAYER_NoHRM>;
        };

        // F19 combo for Go60 - TailorKey
        combo_F19_cb_v1_TKZ {
            key-positions = <POS_RH_C4R1 POS_RH_C4R2>;
            bindings = <&kp F19>;
            layers = <LAYER_Home LAYER_Qwerty LAYER_LeftPinky LAYER_LeftRingy LAYER_LeftMiddy LAYER_LeftIndex LAYER_RightPinky LAYER_RightRingy LAYER_RightMiddy LAYER_RightIndex LAYER_NoHRM>;
        };

        // F20 combo for Go60 - TailorKey
        combo_F20_cb_v1_TKZ {
            key-positions = <POS_RH_C5R1 POS_RH_C5R2>;
            bindings = <&kp F20>;
            layers = <LAYER_Home LAYER_Qwerty LAYER_LeftPinky LAYER_LeftRingy LAYER_LeftMiddy LAYER_LeftIndex LAYER_RightPinky LAYER_RightRingy LAYER_RightMiddy LAYER_RightIndex LAYER_NoHRM>;
        };

        // sticky "hyper" modifiers (Win + Alt + Ctrl + Shift) - TailorKey
        combo_sticky_hyp_rght_v1_TKZ {
            timeout-ms = <50>;
            key-positions = <POS_RH_C2R4 POS_RH_C2R5>;
            bindings = <&sk LG(LA(LC(LSHFT)))>;
            layers = <LAYER_Home LAYER_Qwerty LAYER_NoHRM>;
        };

        // sticky "meh" modifiers (Alt + Ctrl + Shift) - TailorKey
        combo_sticky_meh_rght_v1_TKZ {
            timeout-ms = <50>;
            key-positions = <POS_RH_C3R5 POS_RH_C3R4>;
            bindings = <&sk LA(LC(LSHFT))>;
            layers = <LAYER_Home LAYER_Qwerty LAYER_NoHRM>;
        };

        // Alt Tab Switcher (Cursor Layer) - TailorKey
        combo_tabswitch_alt_v1_TKZ {
            key-positions = <POS_LH_T1 POS_LH_C1R4>;
            bindings = <&mod_tab_chord_v2_TKZ LALT LAYER_Navigation>;
            layers = <LAYER_Home LAYER_Qwerty LAYER_NoHRM>;
        };

        // Alt Tab Switcher (Cursor Layer) - TailorKey
        combo_tabswitch_ctrl_v1_TKZ {
            key-positions = <POS_LH_C2R5 POS_LH_C2R4>;
            bindings = <&mod_tab_chord_v2_TKZ LCTRL LAYER_Navigation>;
            layers = <LAYER_Home LAYER_Qwerty LAYER_NoHRM>;
        };
    };
};

/* Automatically generated keymap */
/ {
    keymap {
        compatible = "zmk,keymap";


        layer_Home {
            bindings = <
 &mt GRAVE ESC         &fn_num_1 0 F1                 &fn_num_2 0 F2                   &fn_num_3 0 F3                     &fn_num_4 0 F4  &fn_num_5 0 F5                                                                                                                                          &fn_num_6 0 F6                    &fn_num_7 0 F7                    &fn_num_8 0 F8                  &fn_num_9 0 F9                     &fn_num_0 0 F10                              &kp MINUS
       &kp TAB                  &kp B                          &kp L                            &kp D                              &kp C           &kp V                                                                                                                                                   &kp J                             &kp Y                             &kp O                           &kp U                            &kp SEMI  &mod_tap_primary_preferred BSLH EQUAL
     &kp LSHFT  &lt LAYER_Shortcuts N  &HRM_left_ring_v1B_TKZ LALT R  &HRM_left_middy_v1B_TKZ LCTRL T    &HRM_left_index_v1B_TKZ LSHFT S           &kp G                                                                                                                                                   &kp P  &HRM_right_index_v1B_TKZ RSHFT H  &HRM_right_middy_v1B_TKZ RCTRL A  &HRM_right_ring_v1B_TKZ LALT E  &mod_tap_primary_preferred LS(I) I                                &kp SQT
     &kp LCTRL                  &kp X                          &kp Q                            &kp M                              &kp W           &kp Z                                                                                                                                                   &kp K                             &kp F                         &kp COMMA                         &kp DOT                      &inv_slash 0 0                       &to LAYER_Keypad
                                                            &kp LGUI                         &kp LALT  &lt LAYER_WindowsAndSymbols SPACE                                                                                                                                                                               &td_LAYER_WindowsAndSymbols                             &none            &magic LAYER_Magic 0
                                                                                                                                                          &thumb_v2_TKZ LAYER_Navigation BSPC  &thumb_v2_TKZ LAYER_Keypad DEL  &to_layer_tap LAYER_Home RET  &td_LAYER_Mouse  &kp RET  &kp SPACE
            >;
        };

        layer_NoHRM {
            bindings = <
 &trans  &trans  &trans  &trans  &trans  &trans                                                  &trans  &trans  &trans  &trans  &trans  &trans
 &trans  &trans  &trans  &trans  &trans  &trans                                                  &trans  &trans  &trans  &trans  &trans  &trans
 &trans  &trans   &kp R   &kp T   &kp S  &trans                                                  &trans   &kp H   &kp A   &kp E  &trans  &trans
 &trans  &trans  &trans  &trans  &trans  &trans                                                  &trans  &trans  &trans  &trans  &trans  &trans
                 &trans  &trans  &trans                                                                  &trans  &trans  &trans
                                                 &trans  &trans  &trans  &trans  &trans  &trans
            >;
        };

        layer_Qwerty {
            bindings = <
 &trans  &trans  &trans  &trans  &trans  &trans                                                  &trans  &trans     &trans   &trans    &trans  &trans
 &trans   &kp Q   &kp W   &kp E   &kp R   &kp T                                                   &kp Y   &kp U      &kp I    &kp O     &kp P  &trans
 &trans   &kp A   &kp S   &kp D   &kp F   &kp G                                                   &kp H   &kp J      &kp K    &kp L  &kp SEMI  &trans
 &trans   &kp Z   &kp X   &kp C   &kp V   &kp B                                                   &kp N   &kp M  &kp COMMA  &kp DOT  &kp FSLH  &trans
                 &trans  &trans  &trans                                                                  &trans     &trans   &trans
                                                 &trans  &trans  &trans  &trans  &trans  &trans
            >;
        };

        layer_Navigation {
            bindings = <
         &none      &none                    &none                    &none                    &none            &none                                                       &kp K_APP  &kp LS(TAB)        &kp TAB  &kp PAUSE_BREAK   &none     &trans
         &none      &none  &cur_SELECT_NONE_v1_TKZ  &cur_EXTEND_LINE_v1_TKZ  &cur_EXTEND_WORD_v1_TKZ            &none                                                       &kp PG_UP     &kp HOME         &kp UP          &kp END  &trans     &trans
 &kp LC(LS(Z))  &kp LC(A)                 &kp LALT                &kp LCTRL                &kp LSHFT   &to LAYER_Home                                                       &kp PG_DN     &kp LEFT       &kp DOWN        &kp RIGHT   &none     &trans
     &kp LC(Y)  &kp LC(Z)                &kp LC(X)                &kp LC(C)                &kp LC(V)  &to LAYER_NoHRM                                                           &none        &none          &none            &none  &trans  &kp LC(L)
                                             &none                    &none                    &none                                                                                     &kp LC(F)  &kp LC(LS(G))        &kp LC(G)
                                                                                                                        &none  &trans  &trans   &none  &kp LS(RET)  &trans
            >;
        };

        layer_Keypad {
            bindings = <
     &none      &none     &none     &none      &none      &none                                                   &kp ESC      &none  &kp KP_MULTIPLY  &kp KP_SLASH  &kp KP_MINUS           &none
     &none      &none  &kp HOME    &kp UP    &kp END  &kp PG_UP                                                   &kp DEL  &kp KP_N7        &kp KP_N8     &kp KP_N9   &kp KP_PLUS           &none
 &kp LC(Y)  &kp LC(Z)  &kp LEFT  &kp DOWN  &kp RIGHT  &kp PG_DN                                                  &kp BSPC  &kp KP_N4        &kp KP_N5     &kp KP_N6     &kp EQUAL           &none
     &none  &kp LC(Z)     &none     &none      &none      &none                                                     &none  &kp KP_N1        &kp KP_N2     &kp KP_N3  &kp KP_ENTER  &to LAYER_Home
                         &trans    &trans     &trans                                                                       &kp KP_N0        &kp KP_N0    &kp KP_DOT
                                                                 &trans  &trans  &trans  &trans  &trans  &trans
            >;
        };

        layer_Shortcuts {
            bindings = <
  &none  &kp LC(LA(LS(F13)))  &kp LC(LA(LS(F14)))  &kp LC(LA(LS(F15)))  &kp LC(LA(LS(F16)))  &kp LC(LA(LS(F17)))                                                         &none       &kp LBKT      &kp MINUS      &kp RBKT   &none   &none
  &none                &none                &none            &kp LC(D)                &none                &none                                                    &kp LS(N7)   &kp LS(LBKT)  &kp LS(EQUAL)  &kp LS(RBKT)   &none   &none
  &none                &none                &none            &kp LC(B)            &kp LA(S)    &kp LS(LA(LC(F)))                                                  &kp LS(BSLH)     &kp LS(N9)      &kp EQUAL    &kp LS(N0)   &none   &none
  &none                &none                &none            &kp LA(B)        &kp LA(LS(S))        &kp LC(LA(Z))                                                         &none  &kp LS(COMMA)     &kp LS(N1)   &kp LS(DOT)   &none   &none
                                            &none                &none                &none                                                                                             &none          &none         &none
                                                                                                                  &trans  &trans  &trans  &trans  &trans  &trans
            >;
        };

        layer_WindowsAndSymbols {
            bindings = <
  &none   &none   &none          &none          &none   &none                                                   &none   &none   &none   &none   &none   &none
  &none   &none   &none      &kp LG(E)          &none   &none                                                   &none   &none   &none   &none   &none   &none
  &none   &none   &none  &kp LG(LC(T))  &kp LG(LS(S))   &none                                                   &none   &none   &none   &none   &none   &none
  &none   &none   &none          &none          &none   &none                                                   &none   &none   &none   &none   &none   &none
                  &none          &none          &none                                                                   &none   &none   &none
                                                               &trans  &trans  &trans  &trans  &trans  &trans
            >;
        };

        layer_Gaming {
            bindings = <
   &kp ESC     &kp N1    &kp N2  &kp N3                       &kp N4  &kp N5                                                     &kp N6    &kp N7    &kp N8         &kp N9       &kp N0      &kp MINUS
   &kp RET    &kp TAB     &kp Q   &kp W                        &kp E   &kp R                                                      &kp Y     &kp U     &kp I          &kp O        &kp P  &kp LS(EQUAL)
 &kp GRAVE  &kp LSHFT     &kp A   &kp S                        &kp D   &kp F                                                      &kp H     &kp J     &kp K          &kp L     &kp SEMI    &kp LS(SQT)
     &kp B  &kp LCTRL     &kp Z   &kp X                        &kp C   &kp V                                                      &kp N     &kp M    &kp UP  &kp LS(COMMA)  &kp LS(DOT)       &kp LGUI
                       &kp LALT   &kp T  &lt LAYER_GamingShortcuts G                                                                     &kp LEFT  &kp DOWN      &kp RIGHT
                                                                              &kp SPACE  &trans  &trans  &trans  &trans  &trans
            >;
        };

        layer_GamingShortcuts {
            bindings = <
  &none   &none   &none   &none          &none   &none                                                   &none   &none   &none   &none   &none   &none
  &none   &none   &none   &kp I          &none   &none                                                   &none   &none   &none   &none   &none   &none
  &none   &none   &none   &kp M  &kp LG(LS(S))   &none                                                   &none   &none   &none   &none   &none   &none
  &none   &none   &none   &none          &none   &none                                                   &none   &none   &none   &none   &none   &none
                  &none   &none          &none                                                                   &none   &none   &none
                                                         &none   &none   &none   &none   &none   &none
            >;
        };

        layer_Magic {
            bindings = <
 &mstr1_v1_TKZ            &none       &sys_reset            &none     &kp C_BRI_DN     &kp C_BRI_UP                                                           &kp PSCRN           &none             &none  &sys_reset   &kp C_VOL_DN  &kp C_VOL_UP
         &none  &rgb_ug RGB_SPI  &rgb_ug RGB_SAI  &rgb_ug RGB_HUI  &rgb_ug RGB_BRI  &rgb_ug RGB_TOG                                                               &none           &none             &none       &none  &kp C_AL_CALC    &kp C_MUTE
         &none  &rgb_ug RGB_SPD  &rgb_ug RGB_SAD  &rgb_ug RGB_HUD  &rgb_ug RGB_BRD  &rgb_ug RGB_EFF                                                          &bt BT_CLR  &bt BT_CLR_ALL             &none       &none          &none         &none
   &bootloader            &none            &bt_0            &bt_1            &bt_2            &bt_3                                                          &kp C_PREV      &kp C_NEXT          &kp C_PP       &none          &none   &bootloader
                                    &out OUT_USB            &none            &none                                                                                                &none  &to LAYER_Qwerty       &none
                                                                                                     &kp CAPS  &kp KP_NUM  &kp SLCK   &none   &none   &none
            >;
        };

        layer_Mouse {
            bindings = <
  &none           &none                &none                &none                &none           &none                                                                                   &none                &none                &none                &none      &none     &none
  &none           &none       &msc SCRL_LEFT         &mmv MOVE_UP      &msc SCRL_RIGHT           &none                                                                                   &none            &sk RSHFT            &sk RCTRL             &sk RALT   &sk RGUI     &none
  &none    &msc SCRL_UP       &mmv MOVE_LEFT       &mmv MOVE_DOWN      &mmv MOVE_RIGHT    &msc SCRL_UP                                                                            &msc SCRL_UP  &mo LAYER_MouseFast  &mo LAYER_MouseWarp  &mo LAYER_MouseSlow  &mkp LCLK  &mkp MB4
  &none  &msc SCRL_DOWN  &mo LAYER_MouseSlow  &mo LAYER_MouseWarp  &mo LAYER_MouseFast  &msc SCRL_DOWN                                                                          &msc SCRL_DOWN       &msc SCRL_LEFT         &mmv MOVE_UP      &msc SCRL_RIGHT  &mkp RCLK  &mkp MB5
                                   &kp LC(X)            &kp LC(C)            &kp LC(V)                                                                                                               &mmv MOVE_LEFT       &mmv MOVE_DOWN      &mmv MOVE_RIGHT
                                                                                                        &mkp LCLK  &mkp RCLK  &mkp MB4  &mkp LCLK  &tog LAYER_Mouse  &mkp RCLK
            >;
        };

        layer_MouseSlow {
            bindings = <
 &trans  &trans  &trans  &trans  &trans  &trans                                                  &trans  &trans  &trans  &trans  &trans  &trans
 &trans  &trans  &trans  &trans  &trans  &trans                                                  &trans  &trans  &trans  &trans  &trans  &trans
 &trans  &trans  &trans  &trans  &trans  &trans                                                  &trans  &trans  &trans  &trans  &trans  &trans
 &trans  &trans  &trans  &trans  &trans  &trans                                                  &trans  &trans  &trans  &trans  &trans  &trans
                 &trans  &trans  &trans                                                                  &trans  &trans  &trans
                                                 &trans  &trans  &trans  &trans  &trans  &trans
            >;
        };

        layer_MouseFast {
            bindings = <
 &trans  &trans  &trans  &trans  &trans  &trans                                                  &trans  &trans  &trans  &trans  &trans  &trans
 &trans  &trans  &trans  &trans  &trans  &trans                                                  &trans  &trans  &trans  &trans  &trans  &trans
 &trans  &trans  &trans  &trans  &trans  &trans                                                  &trans  &trans  &trans  &trans  &trans  &trans
 &trans  &trans  &trans  &trans  &trans  &trans                                                  &trans  &trans  &trans  &trans  &trans  &trans
                 &trans  &trans  &trans                                                                  &trans  &trans  &trans
                                                 &trans  &trans  &trans  &trans  &trans  &trans
            >;
        };

        layer_MouseWarp {
            bindings = <
 &trans  &trans  &trans  &trans  &trans  &trans                                                  &trans  &trans  &trans  &trans  &trans  &trans
 &trans  &trans  &trans  &trans  &trans  &trans                                                  &trans  &trans  &trans  &trans  &trans  &trans
 &trans  &trans  &trans  &trans  &trans  &trans                                                  &trans  &trans  &trans  &trans  &trans  &trans
 &trans  &trans  &trans  &trans  &trans  &trans                                                  &trans  &trans  &trans  &trans  &trans  &trans
                 &trans  &trans  &trans                                                                  &trans  &trans  &trans
                                                 &trans  &trans  &trans  &trans  &trans  &trans
            >;
        };

        layer_LeftPinky {
            bindings = <
 &trans  &HRM_left_pinky_tap_v1B_TKZ N1       &HRM_left_pinky_tap_v1B_TKZ N2         &HRM_left_pinky_tap_v1B_TKZ N3         &HRM_left_pinky_tap_v1B_TKZ N4  &HRM_left_pinky_tap_v1B_TKZ N5                                                  &trans  &trans  &trans  &trans  &trans  &trans
 &trans   &HRM_left_pinky_tap_v1B_TKZ B        &HRM_left_pinky_tap_v1B_TKZ L          &HRM_left_pinky_tap_v1B_TKZ D          &HRM_left_pinky_tap_v1B_TKZ C   &HRM_left_pinky_tap_v1B_TKZ V                                                  &trans  &trans  &trans  &trans  &trans  &trans
 &trans                           &none  &HRM_left_pinky_ring_v1B_TKZ LALT R  &HRM_left_pinky_middy_v1B_TKZ LCTRL T  &HRM_left_pinky_index_v1B_TKZ LSHFT S   &HRM_left_pinky_tap_v1B_TKZ G                                                  &trans   &kp H   &kp A   &kp E   &kp I  &trans
 &trans   &HRM_left_pinky_tap_v1B_TKZ X        &HRM_left_pinky_tap_v1B_TKZ Q          &HRM_left_pinky_tap_v1B_TKZ M          &HRM_left_pinky_tap_v1B_TKZ W   &HRM_left_pinky_tap_v1B_TKZ Z                                                  &trans  &trans  &trans  &trans  &trans  &trans
                                                                      &trans                                 &trans                                 &trans                                                                                          &trans  &trans  &trans
                                                                                                                                                                                            &trans  &trans  &trans  &trans  &trans  &trans
            >;
        };

        layer_LeftRingy {
            bindings = <
 &trans        &HRM_left_ring_tap_v1B_TKZ N1  &HRM_left_ring_tap_v1B_TKZ N2         &HRM_left_ring_tap_v1B_TKZ N3         &HRM_left_ring_tap_v1B_TKZ N4  &HRM_left_ring_tap_v1B_TKZ N5                                                  &trans  &trans  &trans  &trans  &trans  &trans
 &trans         &HRM_left_ring_tap_v1B_TKZ B   &HRM_left_ring_tap_v1B_TKZ L          &HRM_left_ring_tap_v1B_TKZ D          &HRM_left_ring_tap_v1B_TKZ C   &HRM_left_ring_tap_v1B_TKZ V                                                  &trans  &trans  &trans  &trans  &trans  &trans
 &trans  &HRM_left_ring_pinky_v1B_TKZ LGUI N                          &none  &HRM_left_ring_middy_v1B_TKZ LCTRL T  &HRM_left_ring_index_v1B_TKZ LSHFT S   &HRM_left_ring_tap_v1B_TKZ G                                                  &trans   &kp H   &kp A   &kp E   &kp I  &trans
 &trans         &HRM_left_ring_tap_v1B_TKZ X   &HRM_left_ring_tap_v1B_TKZ Q          &HRM_left_ring_tap_v1B_TKZ M          &HRM_left_ring_tap_v1B_TKZ W   &HRM_left_ring_tap_v1B_TKZ Z                                                  &trans  &trans  &trans  &trans  &trans  &trans
                                                                     &trans                                &trans                                &trans                                                                                         &trans  &trans  &trans
                                                                                                                                                                                        &trans  &trans  &trans  &trans  &trans  &trans
            >;
        };

        layer_LeftMiddy {
            bindings = <
 &trans        &HRM_left_middy_tap_v1B_TKZ N1       &HRM_left_middy_tap_v1B_TKZ N2  &HRM_left_middy_tap_v1B_TKZ N3         &HRM_left_middy_tap_v1B_TKZ N4  &HRM_left_middy_tap_v1B_TKZ N5                                                  &trans  &trans  &trans  &trans  &trans  &trans
 &trans         &HRM_left_middy_tap_v1B_TKZ B        &HRM_left_middy_tap_v1B_TKZ L   &HRM_left_middy_tap_v1B_TKZ D          &HRM_left_middy_tap_v1B_TKZ C   &HRM_left_middy_tap_v1B_TKZ V                                                  &trans  &trans  &trans  &trans  &trans  &trans
 &trans  &HRM_left_middy_pinky_v1B_TKZ LGUI N  &HRM_left_middy_ring_v1B_TKZ LALT R                           &none  &HRM_left_middy_index_v1B_TKZ LSHFT S   &HRM_left_middy_tap_v1B_TKZ G                                                  &trans   &kp H   &kp A   &kp E   &kp I  &trans
 &trans         &HRM_left_middy_tap_v1B_TKZ X        &HRM_left_middy_tap_v1B_TKZ Q   &HRM_left_middy_tap_v1B_TKZ M          &HRM_left_middy_tap_v1B_TKZ W   &HRM_left_middy_tap_v1B_TKZ Z                                                  &trans  &trans  &trans  &trans  &trans  &trans
                                                                            &trans                          &trans                                 &trans                                                                                          &trans  &trans  &trans
                                                                                                                                                                                           &trans  &trans  &trans  &trans  &trans  &trans
            >;
        };

        layer_LeftIndex {
            bindings = <
 &trans        &HRM_left_index_tap_v1B_TKZ N1     &HRM_left_index_tap_v1B_TKZ N2         &HRM_left_index_tap_v1B_TKZ N3  &HRM_left_index_tap_v1B_TKZ N4  &HRM_left_index_tap_v1B_TKZ N5                                                  &trans  &trans  &trans  &trans  &trans  &trans
 &trans         &HRM_left_index_tap_v1B_TKZ B      &HRM_left_index_tap_v1B_TKZ L          &HRM_left_index_tap_v1B_TKZ D   &HRM_left_index_tap_v1B_TKZ C   &HRM_left_index_tap_v1B_TKZ V                                                  &trans  &trans  &trans  &trans  &trans  &trans
 &trans  &HRM_left_index_pinky_v1B_TKZ LGUI N  &HRM_left_index_ringv1_TKZ LALT R  &HRM_left_index_middy_v1B_TKZ LCTRL T                           &none   &HRM_left_index_tap_v1B_TKZ G                                                  &trans   &kp H   &kp A   &kp E   &kp I  &trans
 &trans         &HRM_left_index_tap_v1B_TKZ X      &HRM_left_index_tap_v1B_TKZ Q          &HRM_left_index_tap_v1B_TKZ M   &HRM_left_index_tap_v1B_TKZ W   &HRM_left_index_tap_v1B_TKZ Z                                                  &trans  &trans  &trans  &trans  &trans  &trans
                                                                          &trans                                 &trans                          &trans                                                                                          &trans  &trans  &trans
                                                                                                                                                                                         &trans  &trans  &trans  &trans  &trans  &trans
            >;
        };

        layer_RightPinky {
            bindings = <
 &trans  &trans  &trans  &trans  &trans  &trans                                                  &HRM_right_pinky_tap_v1B_TKZ N6         &HRM_right_pinky_tap_v1B_TKZ N7         &HRM_right_pinky_tap_v1B_TKZ N8       &HRM_right_pinky_tap_v1B_TKZ N9   &HRM_right_pinky_tap_v1B_TKZ N0  &HRM_right_pinky_tap_v1B_TKZ MINUS
 &trans  &trans  &trans  &trans  &trans  &trans                                                   &HRM_right_pinky_tap_v1B_TKZ J          &HRM_right_pinky_tap_v1B_TKZ Y          &HRM_right_pinky_tap_v1B_TKZ O        &HRM_right_pinky_tap_v1B_TKZ U  &HRM_right_pinky_tap_v1B_TKZ SQT  &HRM_right_pinky_tap_v1B_TKZ EQUAL
 &trans   &kp N   &kp R   &kp T   &kp S  &trans                                                   &HRM_right_pinky_tap_v1B_TKZ P  &HRM_right_pinky_index_v1B_TKZ RSHFT H  &HRM_right_pinky_middy_v1B_TKZ RCTRL A  &HRM_right_pinky_ring_v1B_TKZ LALT E                             &none   &HRM_right_pinky_tap_v1B_TKZ SEMI
 &trans  &trans  &trans  &trans  &trans  &trans                                                   &HRM_right_pinky_tap_v1B_TKZ K          &HRM_right_pinky_tap_v1B_TKZ F      &HRM_right_pinky_tap_v1B_TKZ COMMA      &HRM_right_pinky_tap_v1B_TKZ DOT                            &trans                              &trans
                 &trans  &trans  &trans                                                                                                                           &trans                                  &trans                                &trans
                                                 &trans  &trans  &trans  &trans  &trans  &trans
            >;
        };

        layer_RightRingy {
            bindings = <
 &trans  &trans  &trans  &trans  &trans  &trans                                                  &HRM_right_ring_tap_v1B_TKZ N6         &HRM_right_ring_tap_v1B_TKZ N7         &HRM_right_ring_tap_v1B_TKZ N8   &HRM_right_ring_tap_v1B_TKZ N9        &HRM_right_ring_tap_v1B_TKZ N0  &HRM_right_ring_tap_v1B_TKZ MINUS
 &trans  &trans  &trans  &trans  &trans  &trans                                                   &HRM_right_ring_tap_v1B_TKZ J          &HRM_right_ring_tap_v1B_TKZ Y          &HRM_right_ring_tap_v1B_TKZ O    &HRM_right_ring_tap_v1B_TKZ U       &HRM_right_ring_tap_v1B_TKZ SQT  &HRM_right_ring_tap_v1B_TKZ EQUAL
 &trans   &kp N   &kp R   &kp T   &kp S  &trans                                                   &HRM_right_ring_tap_v1B_TKZ P  &HRM_right_ring_index_v1B_TKZ RSHFT H  &HRM_right_ring_middy_v1B_TKZ RCTRL A                            &none  &HRM_right_ring_pinky_v1B_TKZ RGUI I   &HRM_right_ring_tap_v1B_TKZ SEMI
 &trans  &trans  &trans  &trans  &trans  &trans                                                   &HRM_right_ring_tap_v1B_TKZ K          &HRM_right_ring_tap_v1B_TKZ F      &HRM_right_ring_tap_v1B_TKZ COMMA  &HRM_right_ring_tap_v1B_TKZ DOT                                &trans                             &trans
                 &trans  &trans  &trans                                                                                                                         &trans                                 &trans                           &trans
                                                 &trans  &trans  &trans  &trans  &trans  &trans
            >;
        };

        layer_RightMiddy {
            bindings = <
 &trans  &trans  &trans  &trans  &trans  &trans                                                  &HRM_right_middy_tap_v1B_TKZ N6         &HRM_right_middy_tap_v1B_TKZ N7     &HRM_right_middy_tap_v1B_TKZ N8       &HRM_right_middy_tap_v1B_TKZ N9        &HRM_right_middy_tap_v1B_TKZ N0  &HRM_right_middy_tap_v1B_TKZ MINUS
 &trans  &trans  &trans  &trans  &trans  &trans                                                   &HRM_right_middy_tap_v1B_TKZ J          &HRM_right_middy_tap_v1B_TKZ Y      &HRM_right_middy_tap_v1B_TKZ O        &HRM_right_middy_tap_v1B_TKZ U       &HRM_right_middy_tap_v1B_TKZ SQT  &HRM_right_middy_tap_v1B_TKZ EQUAL
 &trans   &kp N   &kp R   &kp T   &kp S  &trans                                                   &HRM_right_middy_tap_v1B_TKZ P  &HRM_right_middy_index_v1B_TKZ RSHFT H                               &none  &HRM_right_middy_ring_v1B_TKZ LALT E  &HRM_right_middy_pinky_v1B_TKZ RGUI I   &HRM_right_middy_tap_v1B_TKZ SEMI
 &trans  &trans  &trans  &trans  &trans  &trans                                                   &HRM_right_middy_tap_v1B_TKZ K          &HRM_right_middy_tap_v1B_TKZ F  &HRM_right_middy_tap_v1B_TKZ COMMA      &HRM_right_middy_tap_v1B_TKZ DOT                                 &trans                              &trans
                 &trans  &trans  &trans                                                                                                                           &trans                              &trans                                &trans
                                                 &trans  &trans  &trans  &trans  &trans  &trans
            >;
        };

        layer_RightIndex {
            bindings = <
 &trans  &trans  &trans  &trans  &trans  &trans                                                  &HRM_right_index_tap_v1B_TKZ N6  &HRM_right_index_tap_v1B_TKZ N7         &HRM_right_index_tap_v1B_TKZ N8       &HRM_right_index_tap_v1B_TKZ N9        &HRM_right_index_tap_v1B_TKZ N0  &HRM_right_index_tap_v1B_TKZ MINUS
 &trans  &trans  &trans  &trans  &trans  &trans                                                   &HRM_right_index_tap_v1B_TKZ J   &HRM_right_index_tap_v1B_TKZ Y          &HRM_right_index_tap_v1B_TKZ O        &HRM_right_index_tap_v1B_TKZ U       &HRM_right_index_tap_v1B_TKZ SQT  &HRM_right_index_tap_v1B_TKZ EQUAL
 &trans   &kp N   &kp R   &kp T   &kp S  &trans                                                   &HRM_right_index_tap_v1B_TKZ P                            &none  &HRM_right_index_middy_v1B_TKZ RCTRL A  &HRM_right_index_ring_v1B_TKZ LALT E  &HRM_right_index_pinky_v1B_TKZ RGUI I   &HRM_right_index_tap_v1B_TKZ SEMI
 &trans  &trans  &trans  &trans  &trans  &trans                                                   &HRM_right_index_tap_v1B_TKZ K   &HRM_right_index_tap_v1B_TKZ F      &HRM_right_index_tap_v1B_TKZ COMMA      &HRM_right_index_tap_v1B_TKZ DOT                                 &trans                              &trans
                 &trans  &trans  &trans                                                                                                                    &trans                                  &trans                                &trans
                                                 &trans  &trans  &trans  &trans  &trans  &trans
            >;
        };

    };
};
